VERSION ""

NS_ :

BS_:

BU_: Cooling DasFront DasRear Ecu Imu Lvac Pedals Pipo Raspberry Steering SteeringWheel TsacMainboard Acquisinator

BO_ 1278 TsacCellboard5Temperature: 8 TsacMainboard
 SG_ group M : 0|4@1+ (1,0) [0|9] "U"  Vector__XXX
 SG_ cell1 m0 : 4|11@1+ (0.1,-50) [-50|125] "degC"  Vector__XXX
 SG_ cell2 m0 : 15|11@1+ (0.1,-50) [-50|125] "degC"  Vector__XXX
 SG_ cell3 m0 : 26|11@1+ (0.1,-50) [-50|125] "degC"  Vector__XXX
 SG_ cell4 m0 : 37|11@1+ (0.1,-50) [-50|125] "degC"  Vector__XXX
 SG_ cell5 m0 : 48|11@1+ (0.1,-50) [-50|125] "degC"  Vector__XXX
 SG_ cell6 m1 : 4|11@1+ (0.1,-50) [-50|125] "degC"  Vector__XXX
 SG_ cell7 m1 : 15|11@1+ (0.1,-50) [-50|126] "degC"  Vector__XXX
 SG_ cell8 m1 : 26|11@1+ (0.1,-50) [-50|125] "degC"  Vector__XXX
 SG_ cell9 m1 : 37|11@1+ (0.1,-50) [-50|125] "degC"  Vector__XXX
 SG_ cell10 m1 : 48|11@1+ (0.1,-50) [-50|125] "degC"  Vector__XXX
 SG_ cell11 m2 : 4|11@1+ (0.1,-50) [-50|125] "degC"  Vector__XXX
 SG_ cell12 m2 : 15|11@1+ (0.1,-50) [-50|125] "degC"  Vector__XXX
 SG_ cell13 m2 : 26|11@1+ (0.1,-50) [-50|125] "degC"  Vector__XXX
 SG_ cell14 m2 : 37|11@1+ (0.1,-50) [-50|125] "degC"  Vector__XXX
 SG_ cell15 m2 : 48|11@1+ (0.1,-50) [-50|125] "degC"  Vector__XXX
 SG_ cell16 m3 : 4|11@1+ (0.1,-50) [-50|125] "degC"  Vector__XXX
 SG_ cell17 m3 : 15|11@1+ (0.1,-50) [-50|125] "degC"  Vector__XXX
 SG_ cell18 m3 : 26|11@1+ (0.1,-50) [-50|125] "degC"  Vector__XXX
 SG_ cell19 m3 : 37|11@1+ (0.1,-50) [-50|125] "degC"  Vector__XXX
 SG_ cell20 m3 : 48|11@1+ (0.1,-50) [-50|125] "degC"  Vector__XXX
 SG_ cell21 m4 : 4|11@1+ (0.1,-50) [-50|125] "degC"  Vector__XXX
 SG_ cell22 m4 : 15|11@1+ (0.1,-50) [-50|125] "degC"  Vector__XXX
 SG_ cell23 m4 : 26|11@1+ (0.1,-50) [-50|125] "degC"  Vector__XXX
 SG_ cell24 m4 : 37|11@1+ (0.1,-50) [-50|125] "degC"  Vector__XXX
 SG_ cell25 m4 : 48|11@1+ (0.1,-50) [-50|125] "degC"  Vector__XXX
 SG_ cell26 m5 : 4|11@1+ (0.1,-50) [-50|125] "degC"  Vector__XXX
 SG_ cell27 m5 : 15|11@1+ (0.1,-50) [-50|125] "degC"  Vector__XXX
 SG_ cell28 m5 : 26|11@1+ (0.1,-50) [-50|125] "degC"  Vector__XXX
 SG_ cell29 m5 : 37|11@1+ (0.1,-50) [-50|125] "degC"  Vector__XXX
 SG_ cell30 m5 : 48|11@1+ (0.1,-50) [-50|125] "degC"  Vector__XXX
 SG_ cell31 m6 : 4|11@1+ (0.1,-50) [-50|125] "degC"  Vector__XXX
 SG_ cell32 m6 : 15|11@1+ (0.1,-50) [-50|125] "degC"  Vector__XXX
 SG_ cell33 m6 : 26|11@1+ (0.1,-50) [-50|125] "degC"  Vector__XXX
 SG_ cell34 m6 : 37|11@1+ (0.1,-50) [-50|125] "degC"  Vector__XXX
 SG_ cell35 m6 : 48|11@1+ (0.1,-50) [-50|125] "degC"  Vector__XXX
 SG_ cell36 m7 : 4|11@1+ (0.1,-50) [-50|125] "degC"  Vector__XXX
 SG_ cell37 m7 : 15|11@1+ (0.1,-50) [-50|125] "degC"  Vector__XXX
 SG_ cell38 m7 : 26|11@1+ (0.1,-50) [-50|125] "degC"  Vector__XXX
 SG_ cell39 m7 : 37|11@1+ (0.1,-50) [-50|125] "degC"  Vector__XXX
 SG_ cell40 m7 : 48|11@1+ (0.1,-50) [-50|125] "degC"  Vector__XXX
 SG_ cell41 m8 : 4|11@1+ (0.1,-50) [-50|125] "degC"  Vector__XXX
 SG_ cell42 m8 : 15|11@1+ (0.1,-50) [-50|125] "degC"  Vector__XXX
 SG_ cell43 m8 : 26|11@1+ (0.1,-50) [-50|125] "degC"  Vector__XXX
 SG_ cell44 m8 : 37|11@1+ (0.1,-50) [-50|125] "degC"  Vector__XXX
 SG_ cell45 m8 : 48|11@1+ (0.1,-50) [-50|125] "degC"  Vector__XXX
 SG_ cell46 m9 : 4|11@1+ (0.1,-50) [-50|125] "degC"  Vector__XXX
 SG_ cell47 m9 : 15|11@1+ (0.1,-50) [-50|125] "degC"  Vector__XXX
 SG_ cell48 m9 : 26|11@1+ (0.1,-50) [-50|125] "degC"  Vector__XXX

BO_ 1279 TsacCellboard6Temperature: 8 TsacMainboard
 SG_ group M : 0|4@1+ (1,0) [0|9] "U"  Vector__XXX
 SG_ cell1 m0 : 4|11@1+ (0.1,-50) [-50|125] "degC"  Vector__XXX
 SG_ cell2 m0 : 15|11@1+ (0.1,-50) [-50|125] "degC"  Vector__XXX
 SG_ cell3 m0 : 26|11@1+ (0.1,-50) [-50|125] "degC"  Vector__XXX
 SG_ cell4 m0 : 37|11@1+ (0.1,-50) [-50|125] "degC"  Vector__XXX
 SG_ cell5 m0 : 48|11@1+ (0.1,-50) [-50|125] "degC"  Vector__XXX
 SG_ cell6 m1 : 4|11@1+ (0.1,-50) [-50|125] "degC"  Vector__XXX
 SG_ cell7 m1 : 15|11@1+ (0.1,-50) [-50|126] "degC"  Vector__XXX
 SG_ cell8 m1 : 26|11@1+ (0.1,-50) [-50|125] "degC"  Vector__XXX
 SG_ cell9 m1 : 37|11@1+ (0.1,-50) [-50|125] "degC"  Vector__XXX
 SG_ cell10 m1 : 48|11@1+ (0.1,-50) [-50|125] "degC"  Vector__XXX
 SG_ cell11 m2 : 4|11@1+ (0.1,-50) [-50|125] "degC"  Vector__XXX
 SG_ cell12 m2 : 15|11@1+ (0.1,-50) [-50|125] "degC"  Vector__XXX
 SG_ cell13 m2 : 26|11@1+ (0.1,-50) [-50|125] "degC"  Vector__XXX
 SG_ cell14 m2 : 37|11@1+ (0.1,-50) [-50|125] "degC"  Vector__XXX
 SG_ cell15 m2 : 48|11@1+ (0.1,-50) [-50|125] "degC"  Vector__XXX
 SG_ cell16 m3 : 4|11@1+ (0.1,-50) [-50|125] "degC"  Vector__XXX
 SG_ cell17 m3 : 15|11@1+ (0.1,-50) [-50|125] "degC"  Vector__XXX
 SG_ cell18 m3 : 26|11@1+ (0.1,-50) [-50|125] "degC"  Vector__XXX
 SG_ cell19 m3 : 37|11@1+ (0.1,-50) [-50|125] "degC"  Vector__XXX
 SG_ cell20 m3 : 48|11@1+ (0.1,-50) [-50|125] "degC"  Vector__XXX
 SG_ cell21 m4 : 4|11@1+ (0.1,-50) [-50|125] "degC"  Vector__XXX
 SG_ cell22 m4 : 15|11@1+ (0.1,-50) [-50|125] "degC"  Vector__XXX
 SG_ cell23 m4 : 26|11@1+ (0.1,-50) [-50|125] "degC"  Vector__XXX
 SG_ cell24 m4 : 37|11@1+ (0.1,-50) [-50|125] "degC"  Vector__XXX
 SG_ cell25 m4 : 48|11@1+ (0.1,-50) [-50|125] "degC"  Vector__XXX
 SG_ cell26 m5 : 4|11@1+ (0.1,-50) [-50|125] "degC"  Vector__XXX
 SG_ cell27 m5 : 15|11@1+ (0.1,-50) [-50|125] "degC"  Vector__XXX
 SG_ cell28 m5 : 26|11@1+ (0.1,-50) [-50|125] "degC"  Vector__XXX
 SG_ cell29 m5 : 37|11@1+ (0.1,-50) [-50|125] "degC"  Vector__XXX
 SG_ cell30 m5 : 48|11@1+ (0.1,-50) [-50|125] "degC"  Vector__XXX
 SG_ cell31 m6 : 4|11@1+ (0.1,-50) [-50|125] "degC"  Vector__XXX
 SG_ cell32 m6 : 15|11@1+ (0.1,-50) [-50|125] "degC"  Vector__XXX
 SG_ cell33 m6 : 26|11@1+ (0.1,-50) [-50|125] "degC"  Vector__XXX
 SG_ cell34 m6 : 37|11@1+ (0.1,-50) [-50|125] "degC"  Vector__XXX
 SG_ cell35 m6 : 48|11@1+ (0.1,-50) [-50|125] "degC"  Vector__XXX
 SG_ cell36 m7 : 4|11@1+ (0.1,-50) [-50|125] "degC"  Vector__XXX
 SG_ cell37 m7 : 15|11@1+ (0.1,-50) [-50|125] "degC"  Vector__XXX
 SG_ cell38 m7 : 26|11@1+ (0.1,-50) [-50|125] "degC"  Vector__XXX
 SG_ cell39 m7 : 37|11@1+ (0.1,-50) [-50|125] "degC"  Vector__XXX
 SG_ cell40 m7 : 48|11@1+ (0.1,-50) [-50|125] "degC"  Vector__XXX
 SG_ cell41 m8 : 4|11@1+ (0.1,-50) [-50|125] "degC"  Vector__XXX
 SG_ cell42 m8 : 15|11@1+ (0.1,-50) [-50|125] "degC"  Vector__XXX
 SG_ cell43 m8 : 26|11@1+ (0.1,-50) [-50|125] "degC"  Vector__XXX
 SG_ cell44 m8 : 37|11@1+ (0.1,-50) [-50|125] "degC"  Vector__XXX
 SG_ cell45 m8 : 48|11@1+ (0.1,-50) [-50|125] "degC"  Vector__XXX
 SG_ cell46 m9 : 4|11@1+ (0.1,-50) [-50|125] "degC"  Vector__XXX
 SG_ cell47 m9 : 15|11@1+ (0.1,-50) [-50|125] "degC"  Vector__XXX
 SG_ cell48 m9 : 26|11@1+ (0.1,-50) [-50|125] "degC"  Vector__XXX

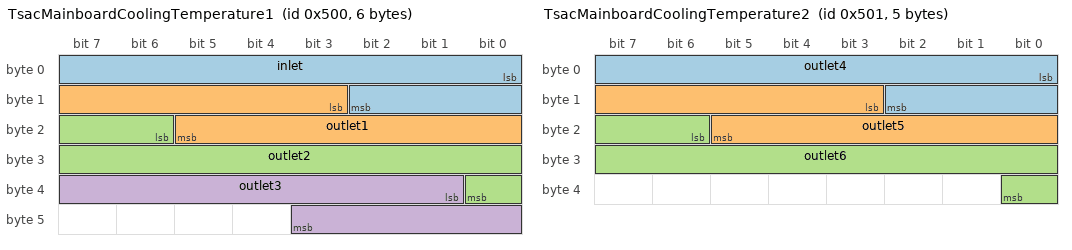
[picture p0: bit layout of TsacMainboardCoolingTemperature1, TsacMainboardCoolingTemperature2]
BO_ 1280 TsacMainboardCoolingTemperature1: 6 TsacMainboard
 SG_ inlet : 0|11@1+ (0.1,-50) [-50|125] "degC"  Vector__XXX
 SG_ outlet1 : 11|11@1+ (0.1,-50) [-50|125] "degC"  Vector__XXX
 SG_ outlet2 : 22|11@1+ (0.1,-50) [-50|125] "degC"  Vector__XXX
 SG_ outlet3 : 33|11@1+ (0.1,-50) [-50|125] "degC"  Vector__XXX

BO_ 1281 TsacMainboardCoolingTemperature2: 5 TsacMainboard
 SG_ outlet4 : 0|11@1+ (0.1,-50) [-50|125] "degC"  Vector__XXX
 SG_ outlet5 : 11|11@1+ (0.1,-50) [-50|125] "degC"  Vector__XXX
 SG_ outlet6 : 22|11@1+ (0.1,-50) [-50|125] "degC"  Vector__XXX

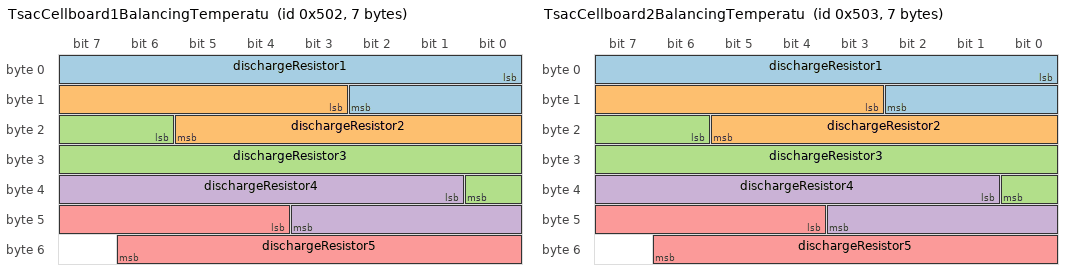
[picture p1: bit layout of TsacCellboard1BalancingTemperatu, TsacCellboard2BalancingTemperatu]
BO_ 1282 TsacCellboard1BalancingTemperatu: 7 TsacMainboard
 SG_ dischargeResistor1 : 0|11@1+ (0.1,-50) [-50|125] "degC"  Vector__XXX
 SG_ dischargeResistor2 : 11|11@1+ (0.1,-50) [-50|125] "degC"  Vector__XXX
 SG_ dischargeResistor3 : 22|11@1+ (0.1,-50) [-50|125] "degC"  Vector__XXX
 SG_ dischargeResistor4 : 33|11@1+ (0.1,-50) [-50|125] "degC"  Vector__XXX
 SG_ dischargeResistor5 : 44|11@1+ (0.1,-50) [-50|125] "degC"  Vector__XXX

BO_ 1283 TsacCellboard2BalancingTemperatu: 7 TsacMainboard
 SG_ dischargeResistor1 : 0|11@1+ (0.1,-50) [-50|125] "degC"  Vector__XXX
 SG_ dischargeResistor2 : 11|11@1+ (0.1,-50) [-50|125] "degC"  Vector__XXX
 SG_ dischargeResistor3 : 22|11@1+ (0.1,-50) [-50|125] "degC"  Vector__XXX
 SG_ dischargeResistor4 : 33|11@1+ (0.1,-50) [-50|125] "degC"  Vector__XXX
 SG_ dischargeResistor5 : 44|11@1+ (0.1,-50) [-50|125] "degC"  Vector__XXX

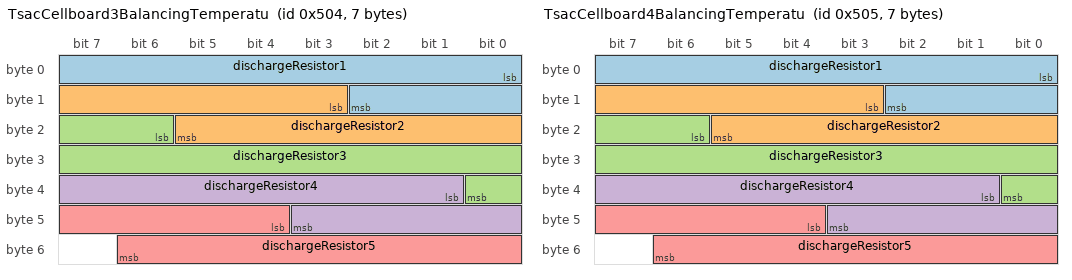
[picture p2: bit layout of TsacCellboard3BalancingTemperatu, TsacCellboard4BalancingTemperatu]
BO_ 1284 TsacCellboard3BalancingTemperatu: 7 TsacMainboard
 SG_ dischargeResistor1 : 0|11@1+ (0.1,-50) [-50|125] "degC"  Vector__XXX
 SG_ dischargeResistor2 : 11|11@1+ (0.1,-50) [-50|125] "degC"  Vector__XXX
 SG_ dischargeResistor3 : 22|11@1+ (0.1,-50) [-50|125] "degC"  Vector__XXX
 SG_ dischargeResistor4 : 33|11@1+ (0.1,-50) [-50|125] "degC"  Vector__XXX
 SG_ dischargeResistor5 : 44|11@1+ (0.1,-50) [-50|125] "degC"  Vector__XXX

BO_ 1285 TsacCellboard4BalancingTemperatu: 7 TsacMainboard
 SG_ dischargeResistor1 : 0|11@1+ (0.1,-50) [-50|125] "degC"  Vector__XXX
 SG_ dischargeResistor2 : 11|11@1+ (0.1,-50) [-50|125] "degC"  Vector__XXX
 SG_ dischargeResistor3 : 22|11@1+ (0.1,-50) [-50|125] "degC"  Vector__XXX
 SG_ dischargeResistor4 : 33|11@1+ (0.1,-50) [-50|125] "degC"  Vector__XXX
 SG_ dischargeResistor5 : 44|11@1+ (0.1,-50) [-50|125] "degC"  Vector__XXX

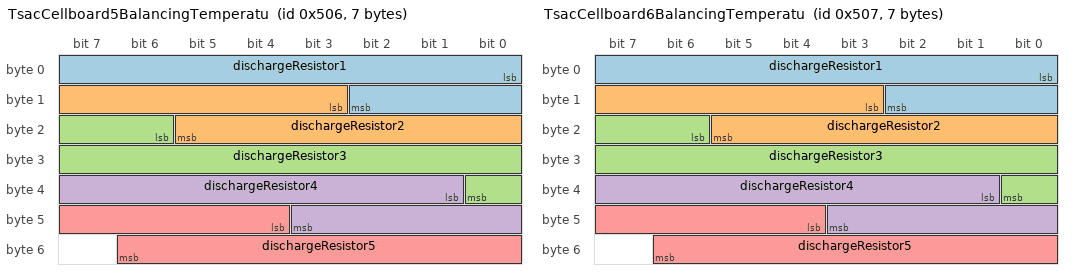
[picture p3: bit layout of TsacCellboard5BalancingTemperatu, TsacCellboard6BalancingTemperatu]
BO_ 1286 TsacCellboard5BalancingTemperatu: 7 TsacMainboard
 SG_ dischargeResistor1 : 0|11@1+ (0.1,-50) [-50|125] "degC"  Vector__XXX
 SG_ dischargeResistor2 : 11|11@1+ (0.1,-50) [-50|125] "degC"  Vector__XXX
 SG_ dischargeResistor3 : 22|11@1+ (0.1,-50) [-50|125] "degC"  Vector__XXX
 SG_ dischargeResistor4 : 33|11@1+ (0.1,-50) [-50|125] "degC"  Vector__XXX
 SG_ dischargeResistor5 : 44|11@1+ (0.1,-50) [-50|125] "degC"  Vector__XXX

BO_ 1287 TsacCellboard6BalancingTemperatu: 7 TsacMainboard
 SG_ dischargeResistor1 : 0|11@1+ (0.1,-50) [-50|125] "degC"  Vector__XXX
 SG_ dischargeResistor2 : 11|11@1+ (0.1,-50) [-50|125] "degC"  Vector__XXX
 SG_ dischargeResistor3 : 22|11@1+ (0.1,-50) [-50|125] "degC"  Vector__XXX
 SG_ dischargeResistor4 : 33|11@1+ (0.1,-50) [-50|125] "degC"  Vector__XXX
 SG_ dischargeResistor5 : 44|11@1+ (0.1,-50) [-50|125] "degC"  Vector__XXX

BO_ 1288 TsacCellboard1Balancing: 3 TsacMainboard
 SG_ cell1 : 0|1@1+ (1,0) [0|1] "bool"  Vector__XXX
 SG_ cell2 : 1|1@1+ (1,0) [0|1] "bool"  Vector__XXX
 SG_ cell3 : 2|1@1+ (1,0) [0|1] "bool"  Vector__XXX
 SG_ cell4 : 3|1@1+ (1,0) [0|1] "bool"  Vector__XXX
 SG_ cell5 : 4|1@1+ (1,0) [0|1] "bool"  Vector__XXX
 SG_ cell6 : 5|1@1+ (1,0) [0|1] "bool"  Vector__XXX
 SG_ cell7 : 6|1@1+ (1,0) [0|1] "bool"  Vector__XXX
 SG_ cell8 : 7|1@1+ (1,0) [0|1] "bool"  Vector__XXX
 SG_ cell9 : 8|1@1+ (1,0) [0|1] "bool"  Vector__XXX
 SG_ cell10 : 9|1@1+ (1,0) [0|1] "bool"  Vector__XXX
 SG_ cell11 : 10|1@1+ (1,0) [0|1] "bool"  Vector__XXX
 SG_ cell12 : 11|1@1+ (1,0) [0|1] "bool"  Vector__XXX
 SG_ cell13 : 12|1@1+ (1,0) [0|1] "bool"  Vector__XXX
 SG_ cell14 : 13|1@1+ (1,0) [0|1] "bool"  Vector__XXX
 SG_ cell15 : 14|1@1+ (1,0) [0|1] "bool"  Vector__XXX
 SG_ cell16 : 15|1@1+ (1,0) [0|1] "bool"  Vector__XXX
 SG_ cell17 : 16|1@1+ (1,0) [0|1] "bool"  Vector__XXX
 SG_ cell18 : 17|1@1+ (1,0) [0|1] "bool"  Vector__XXX
 SG_ cell19 : 18|1@1+ (1,0) [0|1] "bool"  Vector__XXX
 SG_ cell20 : 19|1@1+ (1,0) [0|1] "bool"  Vector__XXX
 SG_ cell21 : 20|1@1+ (1,0) [0|1] "bool"  Vector__XXX
 SG_ cell22 : 21|1@1+ (1,0) [0|1] "bool"  Vector__XXX
 SG_ cell23 : 22|1@1+ (1,0) [0|1] "bool"  Vector__XXX
 SG_ cell24 : 23|1@1+ (1,0) [0|1] "bool"  Vector__XXX

BO_ 1289 TsacCellboard2Balancing: 3 TsacMainboard
 SG_ cell1 : 0|1@1+ (1,0) [0|1] "bool"  Vector__XXX
 SG_ cell2 : 1|1@1+ (1,0) [0|1] "bool"  Vector__XXX
 SG_ cell3 : 2|1@1+ (1,0) [0|1] "bool"  Vector__XXX
 SG_ cell4 : 3|1@1+ (1,0) [0|1] "bool"  Vector__XXX
 SG_ cell5 : 4|1@1+ (1,0) [0|1] "bool"  Vector__XXX
 SG_ cell6 : 5|1@1+ (1,0) [0|1] "bool"  Vector__XXX
 SG_ cell7 : 6|1@1+ (1,0) [0|1] "bool"  Vector__XXX
 SG_ cell8 : 7|1@1+ (1,0) [0|1] "bool"  Vector__XXX
 SG_ cell9 : 8|1@1+ (1,0) [0|1] "bool"  Vector__XXX
 SG_ cell10 : 9|1@1+ (1,0) [0|1] "bool"  Vector__XXX
 SG_ cell11 : 10|1@1+ (1,0) [0|1] "bool"  Vector__XXX
 SG_ cell12 : 11|1@1+ (1,0) [0|1] "bool"  Vector__XXX
 SG_ cell13 : 12|1@1+ (1,0) [0|1] "bool"  Vector__XXX
 SG_ cell14 : 13|1@1+ (1,0) [0|1] "bool"  Vector__XXX
 SG_ cell15 : 14|1@1+ (1,0) [0|1] "bool"  Vector__XXX
 SG_ cell16 : 15|1@1+ (1,0) [0|1] "bool"  Vector__XXX
 SG_ cell17 : 16|1@1+ (1,0) [0|1] "bool"  Vector__XXX
 SG_ cell18 : 17|1@1+ (1,0) [0|1] "bool"  Vector__XXX
 SG_ cell19 : 18|1@1+ (1,0) [0|1] "bool"  Vector__XXX
 SG_ cell20 : 19|1@1+ (1,0) [0|1] "bool"  Vector__XXX
 SG_ cell21 : 20|1@1+ (1,0) [0|1] "bool"  Vector__XXX
 SG_ cell22 : 21|1@1+ (1,0) [0|1] "bool"  Vector__XXX
 SG_ cell23 : 22|1@1+ (1,0) [0|1] "bool"  Vector__XXX
 SG_ cell24 : 23|1@1+ (1,0) [0|1] "bool"  Vector__XXX

BO_ 1290 TsacCellboard3Balancing: 3 TsacMainboard
 SG_ cell1 : 0|1@1+ (1,0) [0|1] "bool"  Vector__XXX
 SG_ cell2 : 1|1@1+ (1,0) [0|1] "bool"  Vector__XXX
 SG_ cell3 : 2|1@1+ (1,0) [0|1] "bool"  Vector__XXX
 SG_ cell4 : 3|1@1+ (1,0) [0|1] "bool"  Vector__XXX
 SG_ cell5 : 4|1@1+ (1,0) [0|1] "bool"  Vector__XXX
 SG_ cell6 : 5|1@1+ (1,0) [0|1] "bool"  Vector__XXX
 SG_ cell7 : 6|1@1+ (1,0) [0|1] "bool"  Vector__XXX
 SG_ cell8 : 7|1@1+ (1,0) [0|1] "bool"  Vector__XXX
 SG_ cell9 : 8|1@1+ (1,0) [0|1] "bool"  Vector__XXX
 SG_ cell10 : 9|1@1+ (1,0) [0|1] "bool"  Vector__XXX
 SG_ cell11 : 10|1@1+ (1,0) [0|1] "bool"  Vector__XXX
 SG_ cell12 : 11|1@1+ (1,0) [0|1] "bool"  Vector__XXX
 SG_ cell13 : 12|1@1+ (1,0) [0|1] "bool"  Vector__XXX
 SG_ cell14 : 13|1@1+ (1,0) [0|1] "bool"  Vector__XXX
 SG_ cell15 : 14|1@1+ (1,0) [0|1] "bool"  Vector__XXX
 SG_ cell16 : 15|1@1+ (1,0) [0|1] "bool"  Vector__XXX
 SG_ cell17 : 16|1@1+ (1,0) [0|1] "bool"  Vector__XXX
 SG_ cell18 : 17|1@1+ (1,0) [0|1] "bool"  Vector__XXX
 SG_ cell19 : 18|1@1+ (1,0) [0|1] "bool"  Vector__XXX
 SG_ cell20 : 19|1@1+ (1,0) [0|1] "bool"  Vector__XXX
 SG_ cell21 : 20|1@1+ (1,0) [0|1] "bool"  Vector__XXX
 SG_ cell22 : 21|1@1+ (1,0) [0|1] "bool"  Vector__XXX
 SG_ cell23 : 22|1@1+ (1,0) [0|1] "bool"  Vector__XXX
 SG_ cell24 : 23|1@1+ (1,0) [0|1] "bool"  Vector__XXX

BO_ 1291 TsacCellboard4Balancing: 3 TsacMainboard
 SG_ cell1 : 0|1@1+ (1,0) [0|1] "bool"  Vector__XXX
 SG_ cell2 : 1|1@1+ (1,0) [0|1] "bool"  Vector__XXX
 SG_ cell3 : 2|1@1+ (1,0) [0|1] "bool"  Vector__XXX
 SG_ cell4 : 3|1@1+ (1,0) [0|1] "bool"  Vector__XXX
 SG_ cell5 : 4|1@1+ (1,0) [0|1] "bool"  Vector__XXX
 SG_ cell6 : 5|1@1+ (1,0) [0|1] "bool"  Vector__XXX
 SG_ cell7 : 6|1@1+ (1,0) [0|1] "bool"  Vector__XXX
 SG_ cell8 : 7|1@1+ (1,0) [0|1] "bool"  Vector__XXX
 SG_ cell9 : 8|1@1+ (1,0) [0|1] "bool"  Vector__XXX
 SG_ cell10 : 9|1@1+ (1,0) [0|1] "bool"  Vector__XXX
 SG_ cell11 : 10|1@1+ (1,0) [0|1] "bool"  Vector__XXX
 SG_ cell12 : 11|1@1+ (1,0) [0|1] "bool"  Vector__XXX
 SG_ cell13 : 12|1@1+ (1,0) [0|1] "bool"  Vector__XXX
 SG_ cell14 : 13|1@1+ (1,0) [0|1] "bool"  Vector__XXX
 SG_ cell15 : 14|1@1+ (1,0) [0|1] "bool"  Vector__XXX
 SG_ cell16 : 15|1@1+ (1,0) [0|1] "bool"  Vector__XXX
 SG_ cell17 : 16|1@1+ (1,0) [0|1] "bool"  Vector__XXX
 SG_ cell18 : 17|1@1+ (1,0) [0|1] "bool"  Vector__XXX
 SG_ cell19 : 18|1@1+ (1,0) [0|1] "bool"  Vector__XXX
 SG_ cell20 : 19|1@1+ (1,0) [0|1] "bool"  Vector__XXX
 SG_ cell21 : 20|1@1+ (1,0) [0|1] "bool"  Vector__XXX
 SG_ cell22 : 21|1@1+ (1,0) [0|1] "bool"  Vector__XXX
 SG_ cell23 : 22|1@1+ (1,0) [0|1] "bool"  Vector__XXX
 SG_ cell24 : 23|1@1+ (1,0) [0|1] "bool"  Vector__XXX

BO_ 1292 TsacCellboard5Balancing: 3 TsacMainboard
 SG_ cell1 : 0|1@1+ (1,0) [0|1] "bool"  Vector__XXX
 SG_ cell2 : 1|1@1+ (1,0) [0|1] "bool"  Vector__XXX
 SG_ cell3 : 2|1@1+ (1,0) [0|1] "bool"  Vector__XXX
 SG_ cell4 : 3|1@1+ (1,0) [0|1] "bool"  Vector__XXX
 SG_ cell5 : 4|1@1+ (1,0) [0|1] "bool"  Vector__XXX
 SG_ cell6 : 5|1@1+ (1,0) [0|1] "bool"  Vector__XXX
 SG_ cell7 : 6|1@1+ (1,0) [0|1] "bool"  Vector__XXX
 SG_ cell8 : 7|1@1+ (1,0) [0|1] "bool"  Vector__XXX
 SG_ cell9 : 8|1@1+ (1,0) [0|1] "bool"  Vector__XXX
 SG_ cell10 : 9|1@1+ (1,0) [0|1] "bool"  Vector__XXX
 SG_ cell11 : 10|1@1+ (1,0) [0|1] "bool"  Vector__XXX
 SG_ cell12 : 11|1@1+ (1,0) [0|1] "bool"  Vector__XXX
 SG_ cell13 : 12|1@1+ (1,0) [0|1] "bool"  Vector__XXX
 SG_ cell14 : 13|1@1+ (1,0) [0|1] "bool"  Vector__XXX
 SG_ cell15 : 14|1@1+ (1,0) [0|1] "bool"  Vector__XXX
 SG_ cell16 : 15|1@1+ (1,0) [0|1] "bool"  Vector__XXX
 SG_ cell17 : 16|1@1+ (1,0) [0|1] "bool"  Vector__XXX
 SG_ cell18 : 17|1@1+ (1,0) [0|1] "bool"  Vector__XXX
 SG_ cell19 : 18|1@1+ (1,0) [0|1] "bool"  Vector__XXX
 SG_ cell20 : 19|1@1+ (1,0) [0|1] "bool"  Vector__XXX
 SG_ cell21 : 20|1@1+ (1,0) [0|1] "bool"  Vector__XXX
 SG_ cell22 : 21|1@1+ (1,0) [0|1] "bool"  Vector__XXX
 SG_ cell23 : 22|1@1+ (1,0) [0|1] "bool"  Vector__XXX
 SG_ cell24 : 23|1@1+ (1,0) [0|1] "bool"  Vector__XXX

BO_ 1293 TsacCellboard6Balancing: 3 TsacMainboard
 SG_ cell1 : 0|1@1+ (1,0) [0|1] "bool"  Vector__XXX
 SG_ cell2 : 1|1@1+ (1,0) [0|1] "bool"  Vector__XXX
 SG_ cell3 : 2|1@1+ (1,0) [0|1] "bool"  Vector__XXX
 SG_ cell4 : 3|1@1+ (1,0) [0|1] "bool"  Vector__XXX
 SG_ cell5 : 4|1@1+ (1,0) [0|1] "bool"  Vector__XXX
 SG_ cell6 : 5|1@1+ (1,0) [0|1] "bool"  Vector__XXX
 SG_ cell7 : 6|1@1+ (1,0) [0|1] "bool"  Vector__XXX
 SG_ cell8 : 7|1@1+ (1,0) [0|1] "bool"  Vector__XXX
 SG_ cell9 : 8|1@1+ (1,0) [0|1] "bool"  Vector__XXX
 SG_ cell10 : 9|1@1+ (1,0) [0|1] "bool"  Vector__XXX
 SG_ cell11 : 10|1@1+ (1,0) [0|1] "bool"  Vector__XXX
 SG_ cell12 : 11|1@1+ (1,0) [0|1] "bool"  Vector__XXX
 SG_ cell13 : 12|1@1+ (1,0) [0|1] "bool"  Vector__XXX
 SG_ cell14 : 13|1@1+ (1,0) [0|1] "bool"  Vector__XXX
 SG_ cell15 : 14|1@1+ (1,0) [0|1] "bool"  Vector__XXX
 SG_ cell16 : 15|1@1+ (1,0) [0|1] "bool"  Vector__XXX
 SG_ cell17 : 16|1@1+ (1,0) [0|1] "bool"  Vector__XXX
 SG_ cell18 : 17|1@1+ (1,0) [0|1] "bool"  Vector__XXX
 SG_ cell19 : 18|1@1+ (1,0) [0|1] "bool"  Vector__XXX
 SG_ cell20 : 19|1@1+ (1,0) [0|1] "bool"  Vector__XXX
 SG_ cell21 : 20|1@1+ (1,0) [0|1] "bool"  Vector__XXX
 SG_ cell22 : 21|1@1+ (1,0) [0|1] "bool"  Vector__XXX
 SG_ cell23 : 22|1@1+ (1,0) [0|1] "bool"  Vector__XXX
 SG_ cell24 : 23|1@1+ (1,0) [0|1] "bool"  Vector__XXX

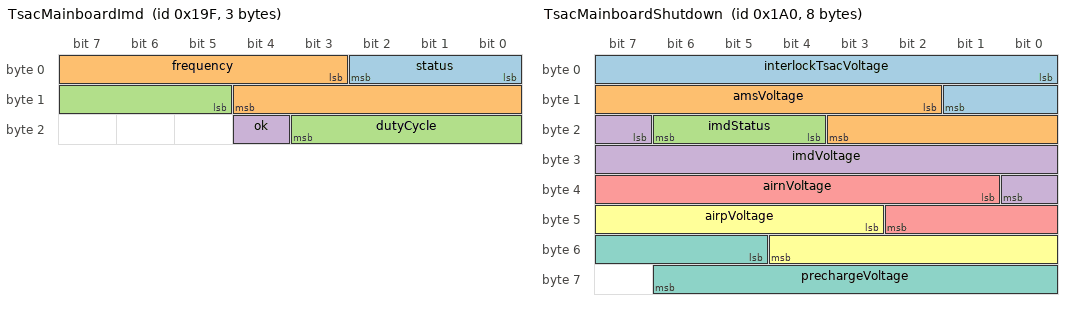
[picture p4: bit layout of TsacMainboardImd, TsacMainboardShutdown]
BO_ 415 TsacMainboardImd: 3 TsacMainboard
 SG_ status : 0|3@1+ (1,0) [0|0] "enum"  Vector__XXX
 SG_ frequency : 3|10@1+ (0.1,0) [0|70] "Hz"  Vector__XXX
 SG_ dutyCycle : 13|7@1+ (0.01,0) [0|1] "U"  Vector__XXX
 SG_ ok : 20|1@1+ (1,0) [0|1] "bool"  Vector__XXX

BO_ 416 TsacMainboardShutdown: 8 TsacMainboard
 SG_ interlockTsacVoltage : 0|10@1+ (0.03,0) [0|27] "V"  Vector__XXX
 SG_ amsVoltage : 10|10@1+ (0.03,0) [0|27] "V"  Vector__XXX
 SG_ imdStatus : 20|3@1+ (1,0) [0|0] "enum"  Vector__XXX
 SG_ imdVoltage : 23|10@1+ (0.03,0) [0|27] "V"  Vector__XXX
 SG_ airnVoltage : 33|10@1+ (0.03,0) [0|27] "V"  Vector__XXX
 SG_ airpVoltage : 43|10@1+ (0.03,0) [0|27] "V"  Vector__XXX
 SG_ prechargeVoltage : 53|10@1+ (0.03,0) [0|27] "V"  Vector__XXX

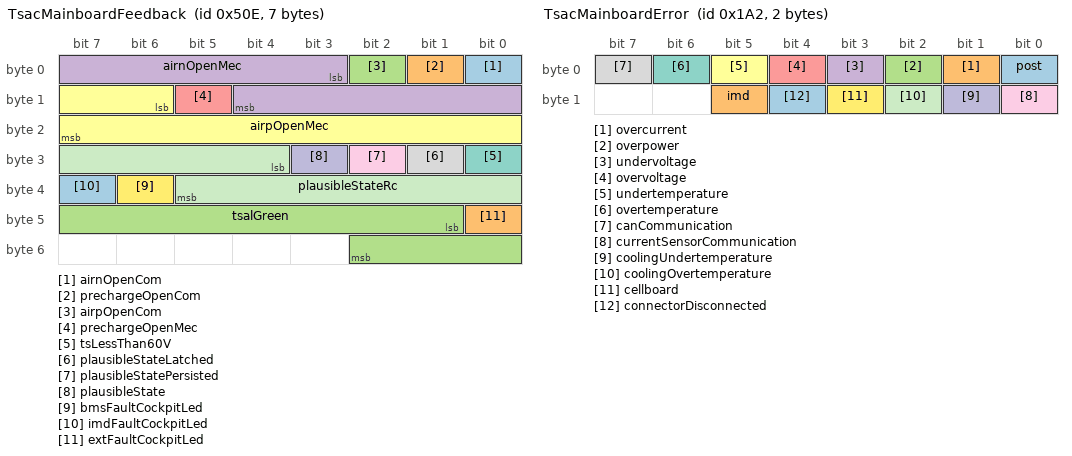
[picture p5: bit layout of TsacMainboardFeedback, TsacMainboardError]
BO_ 1294 TsacMainboardFeedback: 7 TsacMainboard
 SG_ airnOpenCom : 0|1@1+ (1,0) [0|1] "bool"  Vector__XXX
 SG_ prechargeOpenCom : 1|1@1+ (1,0) [0|1] "bool"  Vector__XXX
 SG_ airpOpenCom : 2|1@1+ (1,0) [0|1] "bool"  Vector__XXX
 SG_ airnOpenMec : 3|10@1+ (0.03,0) [0|27] "V"  Vector__XXX
 SG_ prechargeOpenMec : 13|1@1+ (1,0) [0|1] "bool"  Vector__XXX
 SG_ airpOpenMec : 14|10@1+ (0.03,0) [0|27] "V"  Vector__XXX
 SG_ tsLessThan60V : 24|1@1+ (1,0) [0|1] "bool"  Vector__XXX
 SG_ plausibleStateLatched : 25|1@1+ (1,0) [0|1] "bool"  Vector__XXX
 SG_ plausibleStatePersisted : 26|1@1+ (1,0) [0|1] "bool"  Vector__XXX
 SG_ plausibleState : 27|1@1+ (1,0) [0|1] "bool"  Vector__XXX
 SG_ plausibleStateRc : 28|10@1+ (0.03,0) [0|27] "V"  Vector__XXX
 SG_ bmsFaultCockpitLed : 38|1@1+ (1,0) [0|1] "bool"  Vector__XXX
 SG_ imdFaultCockpitLed : 39|1@1+ (1,0) [0|1] "bool"  Vector__XXX
 SG_ extFaultCockpitLed : 40|1@1+ (1,0) [0|1] "bool"  Vector__XXX
 SG_ tsalGreen : 41|10@1+ (0.03,0) [0|27] "V"  Vector__XXX

BO_ 417 TsacMainboardFeedbackShutdown: 3 TsacMainboard
 SG_ sdIn : 0|10@1+ (0.03,0) [0|27] "V"  Vector__XXX
 SG_ sdEnd : 10|10@1+ (0.03,0) [0|27] "V"  Vector__XXX

BO_ 418 TsacMainboardError: 2 TsacMainboard
 SG_ post : 0|1@1+ (1,0) [0|1] "bool"  Vector__XXX
 SG_ overcurrent : 1|1@1+ (1,0) [0|1] "bool"  Vector__XXX
 SG_ overpower : 2|1@1+ (1,0) [0|1] "bool"  Vector__XXX
 SG_ undervoltage : 3|1@1+ (1,0) [0|1] "bool"  Vector__XXX
 SG_ overvoltage : 4|1@1+ (1,0) [0|1] "bool"  Vector__XXX
 SG_ undertemperature : 5|1@1+ (1,0) [0|1] "bool"  Vector__XXX
 SG_ overtemperature : 6|1@1+ (1,0) [0|1] "bool"  Vector__XXX
 SG_ canCommunication : 7|1@1+ (1,0) [0|1] "bool"  Vector__XXX
 SG_ currentSensorCommunication : 8|1@1+ (1,0) [0|1] "bool"  Vector__XXX
 SG_ coolingUndertemperature : 9|1@1+ (1,0) [0|1] "bool"  Vector__XXX
 SG_ coolingOvertemperature : 10|1@1+ (1,0) [0|1] "bool"  Vector__XXX
 SG_ cellboard : 11|1@1+ (1,0) [0|1] "bool"  Vector__XXX
 SG_ connectorDisconnected : 12|1@1+ (1,0) [0|1] "bool"  Vector__XXX
 SG_ imd : 13|1@1+ (1,0) [0|1] "bool"  Vector__XXX

BO_ 419 TsacCellboardErrorA: 6 TsacMainboard
 SG_ cellboard1Post : 0|1@1+ (1,0) [0|1] "bool"  Vector__XXX
 SG_ cellboard1CellUndervoltage : 1|1@1+ (1,0) [0|1] "bool"  Vector__XXX
 SG_ cellboard1CellOvervoltage : 2|1@1+ (1,0) [0|1] "bool"  Vector__XXX
 SG_ cellboard1CellUndertemperature : 3|1@1+ (1,0) [0|1] "bool"  Vector__XXX
 SG_ cellboard1CellOvertemperature : 4|1@1+ (1,0) [0|1] "bool"  Vector__XXX
 SG_ cellboard1DischargeResistorUnder : 5|1@1+ (1,0) [0|1] "bool"  Vector__XXX
 SG_ cellboard1DischargeResistorOvert : 6|1@1+ (1,0) [0|1] "bool"  Vector__XXX
 SG_ cellboard1CanCommunication : 7|1@1+ (1,0) [0|1] "bool"  Vector__XXX
 SG_ cellboard1Flash : 8|1@1+ (1,0) [0|1] "bool"  Vector__XXX
 SG_ cellboard1BmsMonitorCommunicatio : 9|1@1+ (1,0) [0|1] "bool"  Vector__XXX
 SG_ cellboard1OpenWire1 : 10|1@1+ (1,0) [0|1] "bool"  Vector__XXX
 SG_ cellboard1OpenWire2 : 11|1@1+ (1,0) [0|1] "bool"  Vector__XXX
 SG_ cellboard1OpenWire3 : 12|1@1+ (1,0) [0|1] "bool"  Vector__XXX
 SG_ cellboard1OpenWire4 : 13|1@1+ (1,0) [0|1] "bool"  Vector__XXX
 SG_ cellboard1OpenWire5 : 14|1@1+ (1,0) [0|1] "bool"  Vector__XXX
 SG_ cellboard1OpenWire6 : 15|1@1+ (1,0) [0|1] "bool"  Vector__XXX
 SG_ cellboard1OpenWire7 : 16|1@1+ (1,0) [0|1] "bool"  Vector__XXX
 SG_ cellboard1OpenWire8 : 17|1@1+ (1,0) [0|1] "bool"  Vector__XXX
 SG_ cellboard1OpenWire9 : 18|1@1+ (1,0) [0|1] "bool"  Vector__XXX
 SG_ cellboard1OpenWire10 : 19|1@1+ (1,0) [0|1] "bool"  Vector__XXX
 SG_ cellboard1OpenWire11 : 20|1@1+ (1,0) [0|1] "bool"  Vector__XXX
 SG_ cellboard1OpenWire12 : 21|1@1+ (1,0) [0|1] "bool"  Vector__XXX
 SG_ cellboard1OpenWire13 : 22|1@1+ (1,0) [0|1] "bool"  Vector__XXX
 SG_ cellboard2Post : 23|1@1+ (1,0) [0|1] "bool"  Vector__XXX
 SG_ cellboard2CellUndervoltage : 24|1@1+ (1,0) [0|1] "bool"  Vector__XXX
 SG_ cellboard2CellOvervoltage : 25|1@1+ (1,0) [0|1] "bool"  Vector__XXX
 SG_ cellboard2CellUndertemperature : 26|1@1+ (1,0) [0|1] "bool"  Vector__XXX
 SG_ cellboard2CellOvertemperature : 27|1@1+ (1,0) [0|1] "bool"  Vector__XXX
 SG_ cellboard2DischargeResistorUnder : 28|1@1+ (1,0) [0|1] "bool"  Vector__XXX
 SG_ cellboard2DischargeResistorOvert : 29|1@1+ (1,0) [0|1] "bool"  Vector__XXX
 SG_ cellboard2CanCommunication : 30|1@1+ (1,0) [0|1] "bool"  Vector__XXX
 SG_ cellboard2Flash : 31|1@1+ (1,0) [0|1] "bool"  Vector__XXX
 SG_ cellboard2BmsMonitorCommunicatio : 32|1@1+ (1,0) [0|1] "bool"  Vector__XXX
 SG_ cellboard2OpenWire1 : 33|1@1+ (1,0) [0|1] "bool"  Vector__XXX
 SG_ cellboard2OpenWire2 : 34|1@1+ (1,0) [0|1] "bool"  Vector__XXX
 SG_ cellboard2OpenWire3 : 35|1@1+ (1,0) [0|1] "bool"  Vector__XXX
 SG_ cellboard2OpenWire4 : 36|1@1+ (1,0) [0|1] "bool"  Vector__XXX
 SG_ cellboard2OpenWire5 : 37|1@1+ (1,0) [0|1] "bool"  Vector__XXX
 SG_ cellboard2OpenWire6 : 38|1@1+ (1,0) [0|1] "bool"  Vector__XXX
 SG_ cellboard2OpenWire7 : 39|1@1+ (1,0) [0|1] "bool"  Vector__XXX
 SG_ cellboard2OpenWire8 : 40|1@1+ (1,0) [0|1] "bool"  Vector__XXX
 SG_ cellboard2OpenWire9 : 41|1@1+ (1,0) [0|1] "bool"  Vector__XXX
 SG_ cellboard2OpenWire10 : 42|1@1+ (1,0) [0|1] "bool"  Vector__XXX
 SG_ cellboard2OpenWire11 : 43|1@1+ (1,0) [0|1] "bool"  Vector__XXX
 SG_ cellboard2OpenWire12 : 44|1@1+ (1,0) [0|1] "bool"  Vector__XXX
 SG_ cellboard2OpenWire13 : 45|1@1+ (1,0) [0|1] "bool"  Vector__XXX

BO_ 420 TsacCellboardErrorB: 6 TsacMainboard
 SG_ cellboard3Post : 0|1@1+ (1,0) [0|1] "bool"  Vector__XXX
 SG_ cellboard3CellUndervoltage : 1|1@1+ (1,0) [0|1] "bool"  Vector__XXX
 SG_ cellboard3CellOvervoltage : 2|1@1+ (1,0) [0|1] "bool"  Vector__XXX
 SG_ cellboard3CellUndertemperature : 3|1@1+ (1,0) [0|1] "bool"  Vector__XXX
 SG_ cellboard3CellOvertemperature : 4|1@1+ (1,0) [0|1] "bool"  Vector__XXX
 SG_ cellboard3DischargeResistorUnder : 5|1@1+ (1,0) [0|1] "bool"  Vector__XXX
 SG_ cellboard3DischargeResistorOvert : 6|1@1+ (1,0) [0|1] "bool"  Vector__XXX
 SG_ cellboard3CanCommunication : 7|1@1+ (1,0) [0|1] "bool"  Vector__XXX
 SG_ cellboard3Flash : 8|1@1+ (1,0) [0|1] "bool"  Vector__XXX
 SG_ cellboard3BmsMonitorCommunicatio : 9|1@1+ (1,0) [0|1] "bool"  Vector__XXX
 SG_ cellboard3OpenWire1 : 10|1@1+ (1,0) [0|1] "bool"  Vector__XXX
 SG_ cellboard3OpenWire2 : 11|1@1+ (1,0) [0|1] "bool"  Vector__XXX
 SG_ cellboard3OpenWire3 : 12|1@1+ (1,0) [0|1] "bool"  Vector__XXX
 SG_ cellboard3OpenWire4 : 13|1@1+ (1,0) [0|1] "bool"  Vector__XXX
 SG_ cellboard3OpenWire5 : 14|1@1+ (1,0) [0|1] "bool"  Vector__XXX
 SG_ cellboard3OpenWire6 : 15|1@1+ (1,0) [0|1] "bool"  Vector__XXX
 SG_ cellboard3OpenWire7 : 16|1@1+ (1,0) [0|1] "bool"  Vector__XXX
 SG_ cellboard3OpenWire8 : 17|1@1+ (1,0) [0|1] "bool"  Vector__XXX
 SG_ cellboard3OpenWire9 : 18|1@1+ (1,0) [0|1] "bool"  Vector__XXX
 SG_ cellboard3OpenWire10 : 19|1@1+ (1,0) [0|1] "bool"  Vector__XXX
 SG_ cellboard3OpenWire11 : 20|1@1+ (1,0) [0|1] "bool"  Vector__XXX
 SG_ cellboard3OpenWire12 : 21|1@1+ (1,0) [0|1] "bool"  Vector__XXX
 SG_ cellboard3OpenWire13 : 22|1@1+ (1,0) [0|1] "bool"  Vector__XXX
 SG_ cellboard4Post : 23|1@1+ (1,0) [0|1] "bool"  Vector__XXX
 SG_ cellboard4CellUndervoltage : 24|1@1+ (1,0) [0|1] "bool"  Vector__XXX
 SG_ cellboard4CellOvervoltage : 25|1@1+ (1,0) [0|1] "bool"  Vector__XXX
 SG_ cellboard4CellUndertemperature : 26|1@1+ (1,0) [0|1] "bool"  Vector__XXX
 SG_ cellboard4CellOvertemperature : 27|1@1+ (1,0) [0|1] "bool"  Vector__XXX
 SG_ cellboard4DischargeResistorUnder : 28|1@1+ (1,0) [0|1] "bool"  Vector__XXX
 SG_ cellboard4DischargeResistorOvert : 29|1@1+ (1,0) [0|1] "bool"  Vector__XXX
 SG_ cellboard4CanCommunication : 30|1@1+ (1,0) [0|1] "bool"  Vector__XXX
 SG_ cellboard4Flash : 31|1@1+ (1,0) [0|1] "bool"  Vector__XXX
 SG_ cellboard4BmsMonitorCommunicatio : 32|1@1+ (1,0) [0|1] "bool"  Vector__XXX
 SG_ cellboard4OpenWire1 : 33|1@1+ (1,0) [0|1] "bool"  Vector__XXX
 SG_ cellboard4OpenWire2 : 34|1@1+ (1,0) [0|1] "bool"  Vector__XXX
 SG_ cellboard4OpenWire3 : 35|1@1+ (1,0) [0|1] "bool"  Vector__XXX
 SG_ cellboard4OpenWire4 : 36|1@1+ (1,0) [0|1] "bool"  Vector__XXX
 SG_ cellboard4OpenWire5 : 37|1@1+ (1,0) [0|1] "bool"  Vector__XXX
 SG_ cellboard4OpenWire6 : 38|1@1+ (1,0) [0|1] "bool"  Vector__XXX
 SG_ cellboard4OpenWire7 : 39|1@1+ (1,0) [0|1] "bool"  Vector__XXX
 SG_ cellboard4OpenWire8 : 40|1@1+ (1,0) [0|1] "bool"  Vector__XXX
 SG_ cellboard4OpenWire9 : 41|1@1+ (1,0) [0|1] "bool"  Vector__XXX
 SG_ cellboard4OpenWire10 : 42|1@1+ (1,0) [0|1] "bool"  Vector__XXX
 SG_ cellboard4OpenWire11 : 43|1@1+ (1,0) [0|1] "bool"  Vector__XXX
 SG_ cellboard4OpenWire12 : 44|1@1+ (1,0) [0|1] "bool"  Vector__XXX
 SG_ cellboard4OpenWire13 : 45|1@1+ (1,0) [0|1] "bool"  Vector__XXX

BO_ 421 TsacCellboardErrorC: 6 TsacMainboard
 SG_ cellboard5Post : 0|1@1+ (1,0) [0|1] "bool"  Vector__XXX
 SG_ cellboard5CellUndervoltage : 1|1@1+ (1,0) [0|1] "bool"  Vector__XXX
 SG_ cellboard5CellOvervoltage : 2|1@1+ (1,0) [0|1] "bool"  Vector__XXX
 SG_ cellboard5CellUndertemperature : 3|1@1+ (1,0) [0|1] "bool"  Vector__XXX
 SG_ cellboard5CellOvertemperature : 4|1@1+ (1,0) [0|1] "bool"  Vector__XXX
 SG_ cellboard5DischargeResistorUnder : 5|1@1+ (1,0) [0|1] "bool"  Vector__XXX
 SG_ cellboard5DischargeResistorOvert : 6|1@1+ (1,0) [0|1] "bool"  Vector__XXX
 SG_ cellboard5CanCommunication : 7|1@1+ (1,0) [0|1] "bool"  Vector__XXX
 SG_ cellboard5Flash : 8|1@1+ (1,0) [0|1] "bool"  Vector__XXX
 SG_ cellboard5BmsMonitorCommunicatio : 9|1@1+ (1,0) [0|1] "bool"  Vector__XXX
 SG_ cellboard5OpenWire1 : 10|1@1+ (1,0) [0|1] "bool"  Vector__XXX
 SG_ cellboard5OpenWire2 : 11|1@1+ (1,0) [0|1] "bool"  Vector__XXX
 SG_ cellboard5OpenWire3 : 12|1@1+ (1,0) [0|1] "bool"  Vector__XXX
 SG_ cellboard5OpenWire4 : 13|1@1+ (1,0) [0|1] "bool"  Vector__XXX
 SG_ cellboard5OpenWire5 : 14|1@1+ (1,0) [0|1] "bool"  Vector__XXX
 SG_ cellboard5OpenWire6 : 15|1@1+ (1,0) [0|1] "bool"  Vector__XXX
 SG_ cellboard5OpenWire7 : 16|1@1+ (1,0) [0|1] "bool"  Vector__XXX
 SG_ cellboard5OpenWire8 : 17|1@1+ (1,0) [0|1] "bool"  Vector__XXX
 SG_ cellboard5OpenWire9 : 18|1@1+ (1,0) [0|1] "bool"  Vector__XXX
 SG_ cellboard5OpenWire10 : 19|1@1+ (1,0) [0|1] "bool"  Vector__XXX
 SG_ cellboard5OpenWire11 : 20|1@1+ (1,0) [0|1] "bool"  Vector__XXX
 SG_ cellboard5OpenWire12 : 21|1@1+ (1,0) [0|1] "bool"  Vector__XXX
 SG_ cellboard5OpenWire13 : 22|1@1+ (1,0) [0|1] "bool"  Vector__XXX
 SG_ cellboard6Post : 23|1@1+ (1,0) [0|1] "bool"  Vector__XXX
 SG_ cellboard6CellUndervoltage : 24|1@1+ (1,0) [0|1] "bool"  Vector__XXX
 SG_ cellboard6CellOvervoltage : 25|1@1+ (1,0) [0|1] "bool"  Vector__XXX
 SG_ cellboard6CellUndertemperature : 26|1@1+ (1,0) [0|1] "bool"  Vector__XXX
 SG_ cellboard6CellOvertemperature : 27|1@1+ (1,0) [0|1] "bool"  Vector__XXX
 SG_ cellboard6DischargeResistorUnder : 28|1@1+ (1,0) [0|1] "bool"  Vector__XXX
 SG_ cellboard6DischargeResistorOvert : 29|1@1+ (1,0) [0|1] "bool"  Vector__XXX
 SG_ cellboard6CanCommunication : 30|1@1+ (1,0) [0|1] "bool"  Vector__XXX
 SG_ cellboard6Flash : 31|1@1+ (1,0) [0|1] "bool"  Vector__XXX
 SG_ cellboard6BmsMonitorCommunicatio : 32|1@1+ (1,0) [0|1] "bool"  Vector__XXX
 SG_ cellboard6OpenWire1 : 33|1@1+ (1,0) [0|1] "bool"  Vector__XXX
 SG_ cellboard6OpenWire2 : 34|1@1+ (1,0) [0|1] "bool"  Vector__XXX
 SG_ cellboard6OpenWire3 : 35|1@1+ (1,0) [0|1] "bool"  Vector__XXX
 SG_ cellboard6OpenWire4 : 36|1@1+ (1,0) [0|1] "bool"  Vector__XXX
 SG_ cellboard6OpenWire5 : 37|1@1+ (1,0) [0|1] "bool"  Vector__XXX
 SG_ cellboard6OpenWire6 : 38|1@1+ (1,0) [0|1] "bool"  Vector__XXX
 SG_ cellboard6OpenWire7 : 39|1@1+ (1,0) [0|1] "bool"  Vector__XXX
 SG_ cellboard6OpenWire8 : 40|1@1+ (1,0) [0|1] "bool"  Vector__XXX
 SG_ cellboard6OpenWire9 : 41|1@1+ (1,0) [0|1] "bool"  Vector__XXX
 SG_ cellboard6OpenWire10 : 42|1@1+ (1,0) [0|1] "bool"  Vector__XXX
 SG_ cellboard6OpenWire11 : 43|1@1+ (1,0) [0|1] "bool"  Vector__XXX
 SG_ cellboard6OpenWire12 : 44|1@1+ (1,0) [0|1] "bool"  Vector__XXX
 SG_ cellboard6OpenWire13 : 45|1@1+ (1,0) [0|1] "bool"  Vector__XXX

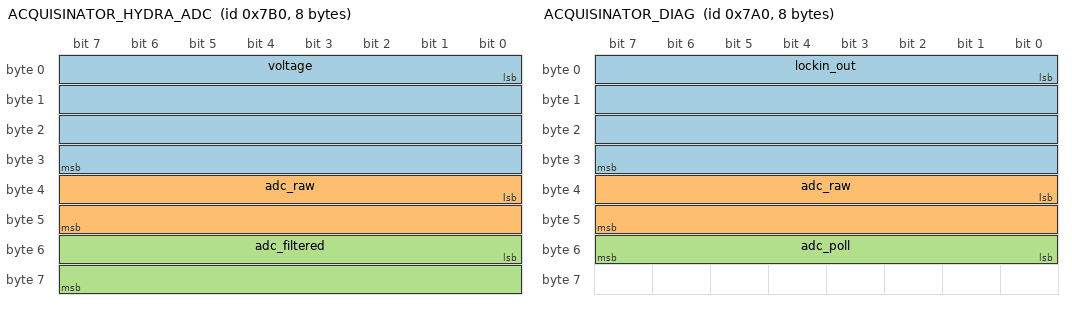
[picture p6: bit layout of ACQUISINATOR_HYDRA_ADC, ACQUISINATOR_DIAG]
BO_ 1968 ACQUISINATOR_HYDRA_ADC: 8 Acquisinator
 SG_ voltage : 0|32@1- (1,0) [0|3290] "mV" Vector__XXX
 SG_ adc_raw : 32|16@1+ (1,0) [0|65535] "code" Vector__XXX
 SG_ adc_filtered : 48|16@1+ (1,0) [0|65535] "code" Vector__XXX

BO_ 1952 ACQUISINATOR_DIAG: 8 Acquisinator
 SG_ lockin_out : 0|32@1+ (1,0) [0|0] "V" Vector__XXX
 SG_ adc_raw : 32|16@1+ (1,0) [0|65535] "code" Vector__XXX
 SG_ adc_poll : 48|8@1+ (1,0) [0|255] "status" Vector__XXX

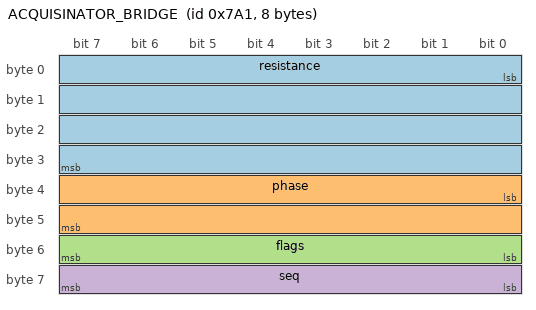
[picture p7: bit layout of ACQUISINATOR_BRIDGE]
BO_ 1953 ACQUISINATOR_BRIDGE: 8 Acquisinator
 SG_ resistance : 0|32@1+ (1,0) [0|0] "ohm" Vector__XXX
 SG_ phase : 32|16@1- (0.01,0) [-180|180] "deg" Vector__XXX
 SG_ flags : 48|8@1+ (1,0) [0|255] "" Vector__XXX
 SG_ seq : 56|8@1+ (1,0) [0|255] "" Vector__XXX

CM_ SG_ 1968 voltage "Tensione sul canale dell'estensimetro (uscita amplificatore), da adc_filtered: 3290 mV * media / 65536";
CM_ SG_ 1968 adc_raw "Ultimo campione dell'LTC1865 (canale SE_CH2), non filtrato; campionamento a 1.5 kHz da timer, frame a ACQUISINATORE_ADC_SEND_RATE";
CM_ SG_ 1968 adc_filtered "Campioni a 1.5 kHz filtrati dal firmware (ACQUISINATORE_ADC_FILTER: media su 20 ms, oppure notch 50/100/150 Hz + passa basso a SEND_RATE/4), arrotondati; voltage ha il valore non arrotondato";
CM_ SG_ 1952 lockin_out "Componente in fase all'uscita dell'amplificatore, ampiezza di picco con segno";
CM_ SG_ 1952 adc_raw "Media dell'uscita dell'amplificatore sulla finestra";
CM_ SG_ 1953 flags "bit0 saturazione bassa, bit1 saturazione alta, bit2 errore SPI, bit3 non calibrato, bit4 nessuna misura (resistance = NaN)";
BA_DEF_ SG_  "StandardName" STRING ;
BA_DEF_ SG_  "SignalTypeName" STRING ;
BA_DEF_ SG_  "SignalType" STRING ;
BA_DEF_ SG_  "Bitfield" STRING ;
BA_DEF_ BO_  "SystemMessageLongSymbol" STRING ;
BA_DEF_ SG_  "SystemSignalLongSymbol" STRING ;
BA_DEF_ BO_  "GenMsgCycleTime" INT 0 65535;
BA_DEF_DEF_  "StandardName" "";
BA_DEF_DEF_  "SignalTypeName" "";
BA_DEF_DEF_  "SignalType" "";
BA_DEF_DEF_  "Bitfield" "false";
BA_DEF_DEF_  "SystemMessageLongSymbol" "";
BA_DEF_DEF_  "SystemSignalLongSymbol" "";
BA_DEF_DEF_  "GenMsgCycleTime" 0;
BA_ "StandardName" SG_ 1278 cell45 "Kraken_TsacCellboard5Temperature_cell45_degC";
BA_ "StandardName" SG_ 1278 cell40 "Kraken_TsacCellboard5Temperature_cell40_degC";
BA_ "StandardName" SG_ 1278 cell35 "Kraken_TsacCellboard5Temperature_cell35_degC";
BA_ "StandardName" SG_ 1278 cell30 "Kraken_TsacCellboard5Temperature_cell30_degC";
BA_ "StandardName" SG_ 1278 cell25 "Kraken_TsacCellboard5Temperature_cell25_degC";
BA_ "StandardName" SG_ 1278 cell20 "Kraken_TsacCellboard5Temperature_cell20_degC";
BA_ "StandardName" SG_ 1278 cell15 "Kraken_TsacCellboard5Temperature_cell15_degC";
BA_ "StandardName" SG_ 1278 cell10 "Kraken_TsacCellboard5Temperature_cell10_degC";
BA_ "StandardName" SG_ 1278 cell5 "Kraken_TsacCellboard5Temperature_cell5_degC";
BA_ "StandardName" SG_ 1278 cell44 "Kraken_TsacCellboard5Temperature_cell44_degC";
BA_ "StandardName" SG_ 1278 cell39 "Kraken_TsacCellboard5Temperature_cell39_degC";
BA_ "StandardName" SG_ 1278 cell34 "Kraken_TsacCellboard5Temperature_cell34_degC";
BA_ "StandardName" SG_ 1278 cell29 "Kraken_TsacCellboard5Temperature_cell29_degC";
BA_ "StandardName" SG_ 1278 cell24 "Kraken_TsacCellboard5Temperature_cell24_degC";
BA_ "StandardName" SG_ 1278 cell19 "Kraken_TsacCellboard5Temperature_cell19_degC";
BA_ "StandardName" SG_ 1278 cell14 "Kraken_TsacCellboard5Temperature_cell14_degC";
BA_ "StandardName" SG_ 1278 cell9 "Kraken_TsacCellboard5Temperature_cell9_degC";
BA_ "StandardName" SG_ 1278 cell4 "Kraken_TsacCellboard5Temperature_cell4_degC";
BA_ "StandardName" SG_ 1278 cell48 "Kraken_TsacCellboard5Temperature_cell48_degC";
BA_ "StandardName" SG_ 1278 cell43 "Kraken_TsacCellboard5Temperature_cell43_degC";
BA_ "StandardName" SG_ 1278 cell38 "Kraken_TsacCellboard5Temperature_cell38_degC";
BA_ "StandardName" SG_ 1278 cell33 "Kraken_TsacCellboard5Temperature_cell33_degC";
BA_ "StandardName" SG_ 1278 cell28 "Kraken_TsacCellboard5Temperature_cell28_degC";
BA_ "StandardName" SG_ 1278 cell23 "Kraken_TsacCellboard5Temperature_cell23_degC";
BA_ "StandardName" SG_ 1278 cell18 "Kraken_TsacCellboard5Temperature_cell18_degC";
BA_ "StandardName" SG_ 1278 cell13 "Kraken_TsacCellboard5Temperature_cell13_degC";
BA_ "StandardName" SG_ 1278 cell8 "Kraken_TsacCellboard5Temperature_cell8_degC";
BA_ "StandardName" SG_ 1278 cell3 "Kraken_TsacCellboard5Temperature_cell3_degC";
BA_ "StandardName" SG_ 1278 cell47 "Kraken_TsacCellboard5Temperature_cell47_degC";
BA_ "StandardName" SG_ 1278 cell42 "Kraken_TsacCellboard5Temperature_cell42_degC";
BA_ "StandardName" SG_ 1278 cell37 "Kraken_TsacCellboard5Temperature_cell37_degC";
BA_ "StandardName" SG_ 1278 cell32 "Kraken_TsacCellboard5Temperature_cell32_degC";
BA_ "StandardName" SG_ 1278 cell27 "Kraken_TsacCellboard5Temperature_cell27_degC";
BA_ "StandardName" SG_ 1278 cell22 "Kraken_TsacCellboard5Temperature_cell22_degC";
BA_ "StandardName" SG_ 1278 cell17 "Kraken_TsacCellboard5Temperature_cell17_degC";
BA_ "StandardName" SG_ 1278 cell12 "Kraken_TsacCellboard5Temperature_cell12_degC";
BA_ "StandardName" SG_ 1278 cell7 "Kraken_TsacCellboard5Temperature_cell7_degC";
BA_ "StandardName" SG_ 1278 cell2 "Kraken_TsacCellboard5Temperature_cell2_degC";
BA_ "StandardName" SG_ 1278 cell46 "Kraken_TsacCellboard5Temperature_cell46_degC";
BA_ "StandardName" SG_ 1278 cell41 "Kraken_TsacCellboard5Temperature_cell41_degC";
BA_ "StandardName" SG_ 1278 cell36 "Kraken_TsacCellboard5Temperature_cell36_degC";
BA_ "StandardName" SG_ 1278 cell31 "Kraken_TsacCellboard5Temperature_cell31_degC";
BA_ "StandardName" SG_ 1278 cell26 "Kraken_TsacCellboard5Temperature_cell26_degC";
BA_ "StandardName" SG_ 1278 cell21 "Kraken_TsacCellboard5Temperature_cell21_degC";
BA_ "StandardName" SG_ 1278 cell16 "Kraken_TsacCellboard5Temperature_cell16_degC";
BA_ "StandardName" SG_ 1278 cell11 "Kraken_TsacCellboard5Temperature_cell11_degC";
BA_ "StandardName" SG_ 1278 cell6 "Kraken_TsacCellboard5Temperature_cell6_degC";
BA_ "StandardName" SG_ 1278 cell1 "Kraken_TsacCellboard5Temperature_cell1_degC";
BA_ "StandardName" SG_ 1279 cell45 "Kraken_TsacCellboard6Temperature_cell45_degC";
BA_ "StandardName" SG_ 1279 cell40 "Kraken_TsacCellboard6Temperature_cell40_degC";
BA_ "StandardName" SG_ 1279 cell35 "Kraken_TsacCellboard6Temperature_cell35_degC";
BA_ "StandardName" SG_ 1279 cell30 "Kraken_TsacCellboard6Temperature_cell30_degC";
BA_ "StandardName" SG_ 1279 cell25 "Kraken_TsacCellboard6Temperature_cell25_degC";
BA_ "StandardName" SG_ 1279 cell20 "Kraken_TsacCellboard6Temperature_cell20_degC";
BA_ "StandardName" SG_ 1279 cell15 "Kraken_TsacCellboard6Temperature_cell15_degC";
BA_ "StandardName" SG_ 1279 cell10 "Kraken_TsacCellboard6Temperature_cell10_degC";
BA_ "StandardName" SG_ 1279 cell5 "Kraken_TsacCellboard6Temperature_cell5_degC";
BA_ "StandardName" SG_ 1279 cell44 "Kraken_TsacCellboard6Temperature_cell44_degC";
BA_ "StandardName" SG_ 1279 cell39 "Kraken_TsacCellboard6Temperature_cell39_degC";
BA_ "StandardName" SG_ 1279 cell34 "Kraken_TsacCellboard6Temperature_cell34_degC";
BA_ "StandardName" SG_ 1279 cell29 "Kraken_TsacCellboard6Temperature_cell29_degC";
BA_ "StandardName" SG_ 1279 cell24 "Kraken_TsacCellboard6Temperature_cell24_degC";
BA_ "StandardName" SG_ 1279 cell19 "Kraken_TsacCellboard6Temperature_cell19_degC";
BA_ "StandardName" SG_ 1279 cell14 "Kraken_TsacCellboard6Temperature_cell14_degC";
BA_ "StandardName" SG_ 1279 cell9 "Kraken_TsacCellboard6Temperature_cell9_degC";
BA_ "StandardName" SG_ 1279 cell4 "Kraken_TsacCellboard6Temperature_cell4_degC";
BA_ "StandardName" SG_ 1279 cell48 "Kraken_TsacCellboard6Temperature_cell48_degC";
BA_ "StandardName" SG_ 1279 cell43 "Kraken_TsacCellboard6Temperature_cell43_degC";
BA_ "StandardName" SG_ 1279 cell38 "Kraken_TsacCellboard6Temperature_cell38_degC";
BA_ "StandardName" SG_ 1279 cell33 "Kraken_TsacCellboard6Temperature_cell33_degC";
BA_ "StandardName" SG_ 1279 cell28 "Kraken_TsacCellboard6Temperature_cell28_degC";
BA_ "StandardName" SG_ 1279 cell23 "Kraken_TsacCellboard6Temperature_cell23_degC";
BA_ "StandardName" SG_ 1279 cell18 "Kraken_TsacCellboard6Temperature_cell18_degC";
BA_ "StandardName" SG_ 1279 cell13 "Kraken_TsacCellboard6Temperature_cell13_degC";
BA_ "StandardName" SG_ 1279 cell8 "Kraken_TsacCellboard6Temperature_cell8_degC";
BA_ "StandardName" SG_ 1279 cell3 "Kraken_TsacCellboard6Temperature_cell3_degC";
BA_ "StandardName" SG_ 1279 cell47 "Kraken_TsacCellboard6Temperature_cell47_degC";
BA_ "StandardName" SG_ 1279 cell42 "Kraken_TsacCellboard6Temperature_cell42_degC";
BA_ "StandardName" SG_ 1279 cell37 "Kraken_TsacCellboard6Temperature_cell37_degC";
BA_ "StandardName" SG_ 1279 cell32 "Kraken_TsacCellboard6Temperature_cell32_degC";
BA_ "StandardName" SG_ 1279 cell27 "Kraken_TsacCellboard6Temperature_cell27_degC";
BA_ "StandardName" SG_ 1279 cell22 "Kraken_TsacCellboard6Temperature_cell22_degC";
BA_ "StandardName" SG_ 1279 cell17 "Kraken_TsacCellboard6Temperature_cell17_degC";
BA_ "StandardName" SG_ 1279 cell12 "Kraken_TsacCellboard6Temperature_cell12_degC";
BA_ "StandardName" SG_ 1279 cell7 "Kraken_TsacCellboard6Temperature_cell7_degC";
BA_ "StandardName" SG_ 1279 cell2 "Kraken_TsacCellboard6Temperature_cell2_degC";
BA_ "StandardName" SG_ 1279 cell46 "Kraken_TsacCellboard6Temperature_cell46_degC";
BA_ "StandardName" SG_ 1279 cell41 "Kraken_TsacCellboard6Temperature_cell41_degC";
BA_ "StandardName" SG_ 1279 cell36 "Kraken_TsacCellboard6Temperature_cell36_degC";
BA_ "StandardName" SG_ 1279 cell31 "Kraken_TsacCellboard6Temperature_cell31_degC";
BA_ "StandardName" SG_ 1279 cell26 "Kraken_TsacCellboard6Temperature_cell26_degC";
BA_ "StandardName" SG_ 1279 cell21 "Kraken_TsacCellboard6Temperature_cell21_degC";
BA_ "StandardName" SG_ 1279 cell16 "Kraken_TsacCellboard6Temperature_cell16_degC";
BA_ "StandardName" SG_ 1279 cell11 "Kraken_TsacCellboard6Temperature_cell11_degC";
BA_ "StandardName" SG_ 1279 cell6 "Kraken_TsacCellboard6Temperature_cell6_degC";
BA_ "StandardName" SG_ 1279 cell1 "Kraken_TsacCellboard6Temperature_cell1_degC";
BA_ "StandardName" SG_ 1280 outlet3 "Kraken_TsacMainboardTemperatureCooling_outlet3_degC";
BA_ "StandardName" SG_ 1280 outlet2 "Kraken_TsacMainboardTemperatureCooling_outlet2_degC";
BA_ "StandardName" SG_ 1280 outlet1 "Kraken_TsacMainboardTemperatureCooling_outlet1_degC";
BA_ "StandardName" SG_ 1280 inlet "Kraken_TsacMainboardTemperatureCooling_inlet_degC";
BA_ "StandardName" SG_ 1281 outlet6 "Kraken_TsacMainboardTemperatureCooling_outlet6_degC";
BA_ "StandardName" SG_ 1281 outlet5 "Kraken_TsacMainboardTemperatureCooling_outlet5_degC";
BA_ "StandardName" SG_ 1281 outlet4 "Kraken_TsacMainboardTemperatureCooling_outlet4_degC";
BA_ "SystemMessageLongSymbol" BO_ 1282 "TsacCellboard1BalancingTemperature";
BA_ "GenMsgCycleTime" BO_ 1282 500;
BA_ "StandardName" SG_ 1282 dischargeResistor5 "Kraken_TsacCellboard1Temperature_dischargeResistor5_degC";
BA_ "StandardName" SG_ 1282 dischargeResistor4 "Kraken_TsacCellboard1Temperature_dischargeResistor4_degC";
BA_ "StandardName" SG_ 1282 dischargeResistor3 "Kraken_TsacCellboard1Temperature_dischargeResistor3_degC";
BA_ "StandardName" SG_ 1282 dischargeResistor2 "Kraken_TsacCellboard1Temperature_dischargeResistor2_degC";
BA_ "StandardName" SG_ 1282 dischargeResistor1 "Kraken_TsacCellboard1Temperature_dischargeResistor1_degC";
BA_ "SystemMessageLongSymbol" BO_ 1283 "TsacCellboard2BalancingTemperature";
BA_ "GenMsgCycleTime" BO_ 1283 500;
BA_ "StandardName" SG_ 1283 dischargeResistor5 "Kraken_TsacCellboard2Temperature_dischargeResistor5_degC";
BA_ "StandardName" SG_ 1283 dischargeResistor4 "Kraken_TsacCellboard2Temperature_dischargeResistor4_degC";
BA_ "StandardName" SG_ 1283 dischargeResistor3 "Kraken_TsacCellboard2Temperature_dischargeResistor3_degC";
BA_ "StandardName" SG_ 1283 dischargeResistor2 "Kraken_TsacCellboard2Temperature_dischargeResistor2_degC";
BA_ "StandardName" SG_ 1283 dischargeResistor1 "Kraken_TsacCellboard2Temperature_dischargeResistor1_degC";
BA_ "SystemMessageLongSymbol" BO_ 1284 "TsacCellboard3BalancingTemperature";
BA_ "GenMsgCycleTime" BO_ 1284 500;
BA_ "StandardName" SG_ 1284 dischargeResistor5 "Kraken_TsacCellboard3Temperature_dischargeResistor5_degC";
BA_ "StandardName" SG_ 1284 dischargeResistor4 "Kraken_TsacCellboard3Temperature_dischargeResistor4_degC";
BA_ "StandardName" SG_ 1284 dischargeResistor3 "Kraken_TsacCellboard3Temperature_dischargeResistor3_degC";
BA_ "StandardName" SG_ 1284 dischargeResistor2 "Kraken_TsacCellboard3Temperature_dischargeResistor2_degC";
BA_ "StandardName" SG_ 1284 dischargeResistor1 "Kraken_TsacCellboard3Temperature_dischargeResistor1_degC";
BA_ "SystemMessageLongSymbol" BO_ 1285 "TsacCellboard4BalancingTemperature";
BA_ "GenMsgCycleTime" BO_ 1285 500;
BA_ "StandardName" SG_ 1285 dischargeResistor5 "Kraken_TsacCellboard4Temperature_dischargeResistor5_degC";
BA_ "StandardName" SG_ 1285 dischargeResistor4 "Kraken_TsacCellboard4Temperature_dischargeResistor4_degC";
BA_ "StandardName" SG_ 1285 dischargeResistor3 "Kraken_TsacCellboard4Temperature_dischargeResistor3_degC";
BA_ "StandardName" SG_ 1285 dischargeResistor2 "Kraken_TsacCellboard4Temperature_dischargeResistor2_degC";
BA_ "StandardName" SG_ 1285 dischargeResistor1 "Kraken_TsacCellboard4Temperature_dischargeResistor1_degC";
BA_ "SystemMessageLongSymbol" BO_ 1286 "TsacCellboard5BalancingTemperature";
BA_ "GenMsgCycleTime" BO_ 1286 500;
BA_ "StandardName" SG_ 1286 dischargeResistor5 "Kraken_TsacCellboard5Temperature_dischargeResistor5_degC";
BA_ "StandardName" SG_ 1286 dischargeResistor4 "Kraken_TsacCellboard5Temperature_dischargeResistor4_degC";
BA_ "StandardName" SG_ 1286 dischargeResistor3 "Kraken_TsacCellboard5Temperature_dischargeResistor3_degC";
BA_ "StandardName" SG_ 1286 dischargeResistor2 "Kraken_TsacCellboard5Temperature_dischargeResistor2_degC";
BA_ "StandardName" SG_ 1286 dischargeResistor1 "Kraken_TsacCellboard5Temperature_dischargeResistor1_degC";
BA_ "SystemMessageLongSymbol" BO_ 1287 "TsacCellboard6BalancingTemperature";
BA_ "GenMsgCycleTime" BO_ 1287 500;
BA_ "StandardName" SG_ 1287 dischargeResistor5 "Kraken_TsacCellboard6Temperature_dischargeResistor5_degC";
BA_ "StandardName" SG_ 1287 dischargeResistor4 "Kraken_TsacCellboard6Temperature_dischargeResistor4_degC";
BA_ "StandardName" SG_ 1287 dischargeResistor3 "Kraken_TsacCellboard6Temperature_dischargeResistor3_degC";
BA_ "StandardName" SG_ 1287 dischargeResistor2 "Kraken_TsacCellboard6Temperature_dischargeResistor2_degC";
BA_ "StandardName" SG_ 1287 dischargeResistor1 "Kraken_TsacCellboard6Temperature_dischargeResistor1_degC";
BA_ "StandardName" SG_ 1288 cell24 "Kraken_TsacCellboard1Balancing_cell24_bool";
BA_ "SignalTypeName" SG_ 1288 cell24 "bool";
BA_ "SignalType" SG_ 1288 cell24 "bool";
BA_ "Bitfield" SG_ 1288 cell24 "true";
BA_ "StandardName" SG_ 1288 cell23 "Kraken_TsacCellboard1Balancing_cell23_bool";
BA_ "SignalTypeName" SG_ 1288 cell23 "bool";
BA_ "SignalType" SG_ 1288 cell23 "bool";
BA_ "Bitfield" SG_ 1288 cell23 "true";
BA_ "StandardName" SG_ 1288 cell22 "Kraken_TsacCellboard1Balancing_cell22_bool";
BA_ "SignalTypeName" SG_ 1288 cell22 "bool";
BA_ "SignalType" SG_ 1288 cell22 "bool";
BA_ "Bitfield" SG_ 1288 cell22 "true";
BA_ "StandardName" SG_ 1288 cell21 "Kraken_TsacCellboard1Balancing_cell21_bool";
BA_ "SignalTypeName" SG_ 1288 cell21 "bool";
BA_ "SignalType" SG_ 1288 cell21 "bool";
BA_ "Bitfield" SG_ 1288 cell21 "true";
BA_ "StandardName" SG_ 1288 cell20 "Kraken_TsacCellboard1Balancing_cell20_bool";
BA_ "SignalTypeName" SG_ 1288 cell20 "bool";
BA_ "SignalType" SG_ 1288 cell20 "bool";
BA_ "Bitfield" SG_ 1288 cell20 "true";
BA_ "StandardName" SG_ 1288 cell19 "Kraken_TsacCellboard1Balancing_cell19_bool";
BA_ "SignalTypeName" SG_ 1288 cell19 "bool";
BA_ "SignalType" SG_ 1288 cell19 "bool";
BA_ "Bitfield" SG_ 1288 cell19 "true";
BA_ "StandardName" SG_ 1288 cell18 "Kraken_TsacCellboard1Balancing_cell18_bool";
BA_ "SignalTypeName" SG_ 1288 cell18 "bool";
BA_ "SignalType" SG_ 1288 cell18 "bool";
BA_ "Bitfield" SG_ 1288 cell18 "true";
BA_ "StandardName" SG_ 1288 cell17 "Kraken_TsacCellboard1Balancing_cell17_bool";
BA_ "SignalTypeName" SG_ 1288 cell17 "bool";
BA_ "SignalType" SG_ 1288 cell17 "bool";
BA_ "Bitfield" SG_ 1288 cell17 "true";
BA_ "StandardName" SG_ 1288 cell16 "Kraken_TsacCellboard1Balancing_cell16_bool";
BA_ "SignalTypeName" SG_ 1288 cell16 "bool";
BA_ "SignalType" SG_ 1288 cell16 "bool";
BA_ "Bitfield" SG_ 1288 cell16 "true";
BA_ "StandardName" SG_ 1288 cell15 "Kraken_TsacCellboard1Balancing_cell15_bool";
BA_ "SignalTypeName" SG_ 1288 cell15 "bool";
BA_ "SignalType" SG_ 1288 cell15 "bool";
BA_ "Bitfield" SG_ 1288 cell15 "true";
BA_ "StandardName" SG_ 1288 cell14 "Kraken_TsacCellboard1Balancing_cell14_bool";
BA_ "SignalTypeName" SG_ 1288 cell14 "bool";
BA_ "SignalType" SG_ 1288 cell14 "bool";
BA_ "Bitfield" SG_ 1288 cell14 "true";
BA_ "StandardName" SG_ 1288 cell13 "Kraken_TsacCellboard1Balancing_cell13_bool";
BA_ "SignalTypeName" SG_ 1288 cell13 "bool";
BA_ "SignalType" SG_ 1288 cell13 "bool";
BA_ "Bitfield" SG_ 1288 cell13 "true";
BA_ "StandardName" SG_ 1288 cell12 "Kraken_TsacCellboard1Balancing_cell12_bool";
BA_ "SignalTypeName" SG_ 1288 cell12 "bool";
BA_ "SignalType" SG_ 1288 cell12 "bool";
BA_ "Bitfield" SG_ 1288 cell12 "true";
BA_ "StandardName" SG_ 1288 cell11 "Kraken_TsacCellboard1Balancing_cell11_bool";
BA_ "SignalTypeName" SG_ 1288 cell11 "bool";
BA_ "SignalType" SG_ 1288 cell11 "bool";
BA_ "Bitfield" SG_ 1288 cell11 "true";
BA_ "StandardName" SG_ 1288 cell10 "Kraken_TsacCellboard1Balancing_cell10_bool";
BA_ "SignalTypeName" SG_ 1288 cell10 "bool";
BA_ "SignalType" SG_ 1288 cell10 "bool";
BA_ "Bitfield" SG_ 1288 cell10 "true";
BA_ "StandardName" SG_ 1288 cell9 "Kraken_TsacCellboard1Balancing_cell9_bool";
BA_ "SignalTypeName" SG_ 1288 cell9 "bool";
BA_ "SignalType" SG_ 1288 cell9 "bool";
BA_ "Bitfield" SG_ 1288 cell9 "true";
BA_ "StandardName" SG_ 1288 cell8 "Kraken_TsacCellboard1Balancing_cell8_bool";
BA_ "SignalTypeName" SG_ 1288 cell8 "bool";
BA_ "SignalType" SG_ 1288 cell8 "bool";
BA_ "Bitfield" SG_ 1288 cell8 "true";
BA_ "StandardName" SG_ 1288 cell7 "Kraken_TsacCellboard1Balancing_cell7_bool";
BA_ "SignalTypeName" SG_ 1288 cell7 "bool";
BA_ "SignalType" SG_ 1288 cell7 "bool";
BA_ "Bitfield" SG_ 1288 cell7 "true";
BA_ "StandardName" SG_ 1288 cell6 "Kraken_TsacCellboard1Balancing_cell6_bool";
BA_ "SignalTypeName" SG_ 1288 cell6 "bool";
BA_ "SignalType" SG_ 1288 cell6 "bool";
BA_ "Bitfield" SG_ 1288 cell6 "true";
BA_ "StandardName" SG_ 1288 cell5 "Kraken_TsacCellboard1Balancing_cell5_bool";
BA_ "SignalTypeName" SG_ 1288 cell5 "bool";
BA_ "SignalType" SG_ 1288 cell5 "bool";
BA_ "Bitfield" SG_ 1288 cell5 "true";
BA_ "StandardName" SG_ 1288 cell4 "Kraken_TsacCellboard1Balancing_cell4_bool";
BA_ "SignalTypeName" SG_ 1288 cell4 "bool";
BA_ "SignalType" SG_ 1288 cell4 "bool";
BA_ "Bitfield" SG_ 1288 cell4 "true";
BA_ "StandardName" SG_ 1288 cell3 "Kraken_TsacCellboard1Balancing_cell3_bool";
BA_ "SignalTypeName" SG_ 1288 cell3 "bool";
BA_ "SignalType" SG_ 1288 cell3 "bool";
BA_ "Bitfield" SG_ 1288 cell3 "true";
BA_ "StandardName" SG_ 1288 cell2 "Kraken_TsacCellboard1Balancing_cell2_bool";
BA_ "SignalTypeName" SG_ 1288 cell2 "bool";
BA_ "SignalType" SG_ 1288 cell2 "bool";
BA_ "Bitfield" SG_ 1288 cell2 "true";
BA_ "StandardName" SG_ 1288 cell1 "Kraken_TsacCellboard1Balancing_cell1_bool";
BA_ "SignalTypeName" SG_ 1288 cell1 "bool";
BA_ "SignalType" SG_ 1288 cell1 "bool";
BA_ "Bitfield" SG_ 1288 cell1 "true";
BA_ "StandardName" SG_ 1289 cell24 "Kraken_TsacCellboard2Balancing_cell24_bool";
BA_ "SignalTypeName" SG_ 1289 cell24 "bool";
BA_ "SignalType" SG_ 1289 cell24 "bool";
BA_ "Bitfield" SG_ 1289 cell24 "true";
BA_ "StandardName" SG_ 1289 cell23 "Kraken_TsacCellboard2Balancing_cell23_bool";
BA_ "SignalTypeName" SG_ 1289 cell23 "bool";
BA_ "SignalType" SG_ 1289 cell23 "bool";
BA_ "Bitfield" SG_ 1289 cell23 "true";
BA_ "StandardName" SG_ 1289 cell22 "Kraken_TsacCellboard2Balancing_cell22_bool";
BA_ "SignalTypeName" SG_ 1289 cell22 "bool";
BA_ "SignalType" SG_ 1289 cell22 "bool";
BA_ "Bitfield" SG_ 1289 cell22 "true";
BA_ "StandardName" SG_ 1289 cell21 "Kraken_TsacCellboard2Balancing_cell21_bool";
BA_ "SignalTypeName" SG_ 1289 cell21 "bool";
BA_ "SignalType" SG_ 1289 cell21 "bool";
BA_ "Bitfield" SG_ 1289 cell21 "true";
BA_ "StandardName" SG_ 1289 cell20 "Kraken_TsacCellboard2Balancing_cell20_bool";
BA_ "SignalTypeName" SG_ 1289 cell20 "bool";
BA_ "SignalType" SG_ 1289 cell20 "bool";
BA_ "Bitfield" SG_ 1289 cell20 "true";
BA_ "StandardName" SG_ 1289 cell19 "Kraken_TsacCellboard2Balancing_cell19_bool";
BA_ "SignalTypeName" SG_ 1289 cell19 "bool";
BA_ "SignalType" SG_ 1289 cell19 "bool";
BA_ "Bitfield" SG_ 1289 cell19 "true";
BA_ "StandardName" SG_ 1289 cell18 "Kraken_TsacCellboard2Balancing_cell18_bool";
BA_ "SignalTypeName" SG_ 1289 cell18 "bool";
BA_ "SignalType" SG_ 1289 cell18 "bool";
BA_ "Bitfield" SG_ 1289 cell18 "true";
BA_ "StandardName" SG_ 1289 cell17 "Kraken_TsacCellboard2Balancing_cell17_bool";
BA_ "SignalTypeName" SG_ 1289 cell17 "bool";
BA_ "SignalType" SG_ 1289 cell17 "bool";
BA_ "Bitfield" SG_ 1289 cell17 "true";
BA_ "StandardName" SG_ 1289 cell16 "Kraken_TsacCellboard2Balancing_cell16_bool";
BA_ "SignalTypeName" SG_ 1289 cell16 "bool";
BA_ "SignalType" SG_ 1289 cell16 "bool";
BA_ "Bitfield" SG_ 1289 cell16 "true";
BA_ "StandardName" SG_ 1289 cell15 "Kraken_TsacCellboard2Balancing_cell15_bool";
BA_ "SignalTypeName" SG_ 1289 cell15 "bool";
BA_ "SignalType" SG_ 1289 cell15 "bool";
BA_ "Bitfield" SG_ 1289 cell15 "true";
BA_ "StandardName" SG_ 1289 cell14 "Kraken_TsacCellboard2Balancing_cell14_bool";
BA_ "SignalTypeName" SG_ 1289 cell14 "bool";
BA_ "SignalType" SG_ 1289 cell14 "bool";
BA_ "Bitfield" SG_ 1289 cell14 "true";
BA_ "StandardName" SG_ 1289 cell13 "Kraken_TsacCellboard2Balancing_cell13_bool";
BA_ "SignalTypeName" SG_ 1289 cell13 "bool";
BA_ "SignalType" SG_ 1289 cell13 "bool";
BA_ "Bitfield" SG_ 1289 cell13 "true";
BA_ "StandardName" SG_ 1289 cell12 "Kraken_TsacCellboard2Balancing_cell12_bool";
BA_ "SignalTypeName" SG_ 1289 cell12 "bool";
BA_ "SignalType" SG_ 1289 cell12 "bool";
BA_ "Bitfield" SG_ 1289 cell12 "true";
BA_ "StandardName" SG_ 1289 cell11 "Kraken_TsacCellboard2Balancing_cell11_bool";
BA_ "SignalTypeName" SG_ 1289 cell11 "bool";
BA_ "SignalType" SG_ 1289 cell11 "bool";
BA_ "Bitfield" SG_ 1289 cell11 "true";
BA_ "StandardName" SG_ 1289 cell10 "Kraken_TsacCellboard2Balancing_cell10_bool";
BA_ "SignalTypeName" SG_ 1289 cell10 "bool";
BA_ "SignalType" SG_ 1289 cell10 "bool";
BA_ "Bitfield" SG_ 1289 cell10 "true";
BA_ "StandardName" SG_ 1289 cell9 "Kraken_TsacCellboard2Balancing_cell9_bool";
BA_ "SignalTypeName" SG_ 1289 cell9 "bool";
BA_ "SignalType" SG_ 1289 cell9 "bool";
BA_ "Bitfield" SG_ 1289 cell9 "true";
BA_ "StandardName" SG_ 1289 cell8 "Kraken_TsacCellboard2Balancing_cell8_bool";
BA_ "SignalTypeName" SG_ 1289 cell8 "bool";
BA_ "SignalType" SG_ 1289 cell8 "bool";
BA_ "Bitfield" SG_ 1289 cell8 "true";
BA_ "StandardName" SG_ 1289 cell7 "Kraken_TsacCellboard2Balancing_cell7_bool";
BA_ "SignalTypeName" SG_ 1289 cell7 "bool";
BA_ "SignalType" SG_ 1289 cell7 "bool";
BA_ "Bitfield" SG_ 1289 cell7 "true";
BA_ "StandardName" SG_ 1289 cell6 "Kraken_TsacCellboard2Balancing_cell6_bool";
BA_ "SignalTypeName" SG_ 1289 cell6 "bool";
BA_ "SignalType" SG_ 1289 cell6 "bool";
BA_ "Bitfield" SG_ 1289 cell6 "true";
BA_ "StandardName" SG_ 1289 cell5 "Kraken_TsacCellboard2Balancing_cell5_bool";
BA_ "SignalTypeName" SG_ 1289 cell5 "bool";
BA_ "SignalType" SG_ 1289 cell5 "bool";
BA_ "Bitfield" SG_ 1289 cell5 "true";
BA_ "StandardName" SG_ 1289 cell4 "Kraken_TsacCellboard2Balancing_cell4_bool";
BA_ "SignalTypeName" SG_ 1289 cell4 "bool";
BA_ "SignalType" SG_ 1289 cell4 "bool";
BA_ "Bitfield" SG_ 1289 cell4 "true";
BA_ "StandardName" SG_ 1289 cell3 "Kraken_TsacCellboard2Balancing_cell3_bool";
BA_ "SignalTypeName" SG_ 1289 cell3 "bool";
BA_ "SignalType" SG_ 1289 cell3 "bool";
BA_ "Bitfield" SG_ 1289 cell3 "true";
BA_ "StandardName" SG_ 1289 cell2 "Kraken_TsacCellboard2Balancing_cell2_bool";
BA_ "SignalTypeName" SG_ 1289 cell2 "bool";
BA_ "SignalType" SG_ 1289 cell2 "bool";
BA_ "Bitfield" SG_ 1289 cell2 "true";
BA_ "StandardName" SG_ 1289 cell1 "Kraken_TsacCellboard2Balancing_cell1_bool";
BA_ "SignalTypeName" SG_ 1289 cell1 "bool";
BA_ "SignalType" SG_ 1289 cell1 "bool";
BA_ "Bitfield" SG_ 1289 cell1 "true";
BA_ "StandardName" SG_ 1290 cell24 "Kraken_TsacCellboard3Balancing_cell24_bool";
BA_ "SignalTypeName" SG_ 1290 cell24 "bool";
BA_ "SignalType" SG_ 1290 cell24 "bool";
BA_ "Bitfield" SG_ 1290 cell24 "true";
BA_ "StandardName" SG_ 1290 cell23 "Kraken_TsacCellboard3Balancing_cell23_bool";
BA_ "SignalTypeName" SG_ 1290 cell23 "bool";
BA_ "SignalType" SG_ 1290 cell23 "bool";
BA_ "Bitfield" SG_ 1290 cell23 "true";
BA_ "StandardName" SG_ 1290 cell22 "Kraken_TsacCellboard3Balancing_cell22_bool";
BA_ "SignalTypeName" SG_ 1290 cell22 "bool";
BA_ "SignalType" SG_ 1290 cell22 "bool";
BA_ "Bitfield" SG_ 1290 cell22 "true";
BA_ "StandardName" SG_ 1290 cell21 "Kraken_TsacCellboard3Balancing_cell21_bool";
BA_ "SignalTypeName" SG_ 1290 cell21 "bool";
BA_ "SignalType" SG_ 1290 cell21 "bool";
BA_ "Bitfield" SG_ 1290 cell21 "true";
BA_ "StandardName" SG_ 1290 cell20 "Kraken_TsacCellboard3Balancing_cell20_bool";
BA_ "SignalTypeName" SG_ 1290 cell20 "bool";
BA_ "SignalType" SG_ 1290 cell20 "bool";
BA_ "Bitfield" SG_ 1290 cell20 "true";
BA_ "StandardName" SG_ 1290 cell19 "Kraken_TsacCellboard3Balancing_cell19_bool";
BA_ "SignalTypeName" SG_ 1290 cell19 "bool";
BA_ "SignalType" SG_ 1290 cell19 "bool";
BA_ "Bitfield" SG_ 1290 cell19 "true";
BA_ "StandardName" SG_ 1290 cell18 "Kraken_TsacCellboard3Balancing_cell18_bool";
BA_ "SignalTypeName" SG_ 1290 cell18 "bool";
BA_ "SignalType" SG_ 1290 cell18 "bool";
BA_ "Bitfield" SG_ 1290 cell18 "true";
BA_ "StandardName" SG_ 1290 cell17 "Kraken_TsacCellboard3Balancing_cell17_bool";
BA_ "SignalTypeName" SG_ 1290 cell17 "bool";
BA_ "SignalType" SG_ 1290 cell17 "bool";
BA_ "Bitfield" SG_ 1290 cell17 "true";
BA_ "StandardName" SG_ 1290 cell16 "Kraken_TsacCellboard3Balancing_cell16_bool";
BA_ "SignalTypeName" SG_ 1290 cell16 "bool";
BA_ "SignalType" SG_ 1290 cell16 "bool";
BA_ "Bitfield" SG_ 1290 cell16 "true";
BA_ "StandardName" SG_ 1290 cell15 "Kraken_TsacCellboard3Balancing_cell15_bool";
BA_ "SignalTypeName" SG_ 1290 cell15 "bool";
BA_ "SignalType" SG_ 1290 cell15 "bool";
BA_ "Bitfield" SG_ 1290 cell15 "true";
BA_ "StandardName" SG_ 1290 cell14 "Kraken_TsacCellboard3Balancing_cell14_bool";
BA_ "SignalTypeName" SG_ 1290 cell14 "bool";
BA_ "SignalType" SG_ 1290 cell14 "bool";
BA_ "Bitfield" SG_ 1290 cell14 "true";
BA_ "StandardName" SG_ 1290 cell13 "Kraken_TsacCellboard3Balancing_cell13_bool";
BA_ "SignalTypeName" SG_ 1290 cell13 "bool";
BA_ "SignalType" SG_ 1290 cell13 "bool";
BA_ "Bitfield" SG_ 1290 cell13 "true";
BA_ "StandardName" SG_ 1290 cell12 "Kraken_TsacCellboard3Balancing_cell12_bool";
BA_ "SignalTypeName" SG_ 1290 cell12 "bool";
BA_ "SignalType" SG_ 1290 cell12 "bool";
BA_ "Bitfield" SG_ 1290 cell12 "true";
BA_ "StandardName" SG_ 1290 cell11 "Kraken_TsacCellboard3Balancing_cell11_bool";
BA_ "SignalTypeName" SG_ 1290 cell11 "bool";
BA_ "SignalType" SG_ 1290 cell11 "bool";
BA_ "Bitfield" SG_ 1290 cell11 "true";
BA_ "StandardName" SG_ 1290 cell10 "Kraken_TsacCellboard3Balancing_cell10_bool";
BA_ "SignalTypeName" SG_ 1290 cell10 "bool";
BA_ "SignalType" SG_ 1290 cell10 "bool";
BA_ "Bitfield" SG_ 1290 cell10 "true";
BA_ "StandardName" SG_ 1290 cell9 "Kraken_TsacCellboard3Balancing_cell9_bool";
BA_ "SignalTypeName" SG_ 1290 cell9 "bool";
BA_ "SignalType" SG_ 1290 cell9 "bool";
BA_ "Bitfield" SG_ 1290 cell9 "true";
BA_ "StandardName" SG_ 1290 cell8 "Kraken_TsacCellboard3Balancing_cell8_bool";
BA_ "SignalTypeName" SG_ 1290 cell8 "bool";
BA_ "SignalType" SG_ 1290 cell8 "bool";
BA_ "Bitfield" SG_ 1290 cell8 "true";
BA_ "StandardName" SG_ 1290 cell7 "Kraken_TsacCellboard3Balancing_cell7_bool";
BA_ "SignalTypeName" SG_ 1290 cell7 "bool";
BA_ "SignalType" SG_ 1290 cell7 "bool";
BA_ "Bitfield" SG_ 1290 cell7 "true";
BA_ "StandardName" SG_ 1290 cell6 "Kraken_TsacCellboard3Balancing_cell6_bool";
BA_ "SignalTypeName" SG_ 1290 cell6 "bool";
BA_ "SignalType" SG_ 1290 cell6 "bool";
BA_ "Bitfield" SG_ 1290 cell6 "true";
BA_ "StandardName" SG_ 1290 cell5 "Kraken_TsacCellboard3Balancing_cell5_bool";
BA_ "SignalTypeName" SG_ 1290 cell5 "bool";
BA_ "SignalType" SG_ 1290 cell5 "bool";
BA_ "Bitfield" SG_ 1290 cell5 "true";
BA_ "StandardName" SG_ 1290 cell4 "Kraken_TsacCellboard3Balancing_cell4_bool";
BA_ "SignalTypeName" SG_ 1290 cell4 "bool";
BA_ "SignalType" SG_ 1290 cell4 "bool";
BA_ "Bitfield" SG_ 1290 cell4 "true";
BA_ "StandardName" SG_ 1290 cell3 "Kraken_TsacCellboard3Balancing_cell3_bool";
BA_ "SignalTypeName" SG_ 1290 cell3 "bool";
BA_ "SignalType" SG_ 1290 cell3 "bool";
BA_ "Bitfield" SG_ 1290 cell3 "true";
BA_ "StandardName" SG_ 1290 cell2 "Kraken_TsacCellboard3Balancing_cell2_bool";
BA_ "SignalTypeName" SG_ 1290 cell2 "bool";
BA_ "SignalType" SG_ 1290 cell2 "bool";
BA_ "Bitfield" SG_ 1290 cell2 "true";
BA_ "StandardName" SG_ 1290 cell1 "Kraken_TsacCellboard3Balancing_cell1_bool";
BA_ "SignalTypeName" SG_ 1290 cell1 "bool";
BA_ "SignalType" SG_ 1290 cell1 "bool";
BA_ "Bitfield" SG_ 1290 cell1 "true";
BA_ "StandardName" SG_ 1291 cell24 "Kraken_TsacCellboard4Balancing_cell24_bool";
BA_ "SignalTypeName" SG_ 1291 cell24 "bool";
BA_ "SignalType" SG_ 1291 cell24 "bool";
BA_ "Bitfield" SG_ 1291 cell24 "true";
BA_ "StandardName" SG_ 1291 cell23 "Kraken_TsacCellboard4Balancing_cell23_bool";
BA_ "SignalTypeName" SG_ 1291 cell23 "bool";
BA_ "SignalType" SG_ 1291 cell23 "bool";
BA_ "Bitfield" SG_ 1291 cell23 "true";
BA_ "StandardName" SG_ 1291 cell22 "Kraken_TsacCellboard4Balancing_cell22_bool";
BA_ "SignalTypeName" SG_ 1291 cell22 "bool";
BA_ "SignalType" SG_ 1291 cell22 "bool";
BA_ "Bitfield" SG_ 1291 cell22 "true";
BA_ "StandardName" SG_ 1291 cell21 "Kraken_TsacCellboard4Balancing_cell21_bool";
BA_ "SignalTypeName" SG_ 1291 cell21 "bool";
BA_ "SignalType" SG_ 1291 cell21 "bool";
BA_ "Bitfield" SG_ 1291 cell21 "true";
BA_ "StandardName" SG_ 1291 cell20 "Kraken_TsacCellboard4Balancing_cell20_bool";
BA_ "SignalTypeName" SG_ 1291 cell20 "bool";
BA_ "SignalType" SG_ 1291 cell20 "bool";
BA_ "Bitfield" SG_ 1291 cell20 "true";
BA_ "StandardName" SG_ 1291 cell19 "Kraken_TsacCellboard4Balancing_cell19_bool";
BA_ "SignalTypeName" SG_ 1291 cell19 "bool";
BA_ "SignalType" SG_ 1291 cell19 "bool";
BA_ "Bitfield" SG_ 1291 cell19 "true";
BA_ "StandardName" SG_ 1291 cell18 "Kraken_TsacCellboard4Balancing_cell18_bool";
BA_ "SignalTypeName" SG_ 1291 cell18 "bool";
BA_ "SignalType" SG_ 1291 cell18 "bool";
BA_ "Bitfield" SG_ 1291 cell18 "true";
BA_ "StandardName" SG_ 1291 cell17 "Kraken_TsacCellboard4Balancing_cell17_bool";
BA_ "SignalTypeName" SG_ 1291 cell17 "bool";
BA_ "SignalType" SG_ 1291 cell17 "bool";
BA_ "Bitfield" SG_ 1291 cell17 "true";
BA_ "StandardName" SG_ 1291 cell16 "Kraken_TsacCellboard4Balancing_cell16_bool";
BA_ "SignalTypeName" SG_ 1291 cell16 "bool";
BA_ "SignalType" SG_ 1291 cell16 "bool";
BA_ "Bitfield" SG_ 1291 cell16 "true";
BA_ "StandardName" SG_ 1291 cell15 "Kraken_TsacCellboard4Balancing_cell15_bool";
BA_ "SignalTypeName" SG_ 1291 cell15 "bool";
BA_ "SignalType" SG_ 1291 cell15 "bool";
BA_ "Bitfield" SG_ 1291 cell15 "true";
BA_ "StandardName" SG_ 1291 cell14 "Kraken_TsacCellboard4Balancing_cell14_bool";
BA_ "SignalTypeName" SG_ 1291 cell14 "bool";
BA_ "SignalType" SG_ 1291 cell14 "bool";
BA_ "Bitfield" SG_ 1291 cell14 "true";
BA_ "StandardName" SG_ 1291 cell13 "Kraken_TsacCellboard4Balancing_cell13_bool";
BA_ "SignalTypeName" SG_ 1291 cell13 "bool";
BA_ "SignalType" SG_ 1291 cell13 "bool";
BA_ "Bitfield" SG_ 1291 cell13 "true";
BA_ "StandardName" SG_ 1291 cell12 "Kraken_TsacCellboard4Balancing_cell12_bool";
BA_ "SignalTypeName" SG_ 1291 cell12 "bool";
BA_ "SignalType" SG_ 1291 cell12 "bool";
BA_ "Bitfield" SG_ 1291 cell12 "true";
BA_ "StandardName" SG_ 1291 cell11 "Kraken_TsacCellboard4Balancing_cell11_bool";
BA_ "SignalTypeName" SG_ 1291 cell11 "bool";
BA_ "SignalType" SG_ 1291 cell11 "bool";
BA_ "Bitfield" SG_ 1291 cell11 "true";
BA_ "StandardName" SG_ 1291 cell10 "Kraken_TsacCellboard4Balancing_cell10_bool";
BA_ "SignalTypeName" SG_ 1291 cell10 "bool";
BA_ "SignalType" SG_ 1291 cell10 "bool";
BA_ "Bitfield" SG_ 1291 cell10 "true";
BA_ "StandardName" SG_ 1291 cell9 "Kraken_TsacCellboard4Balancing_cell9_bool";
BA_ "SignalTypeName" SG_ 1291 cell9 "bool";
BA_ "SignalType" SG_ 1291 cell9 "bool";
BA_ "Bitfield" SG_ 1291 cell9 "true";
BA_ "StandardName" SG_ 1291 cell8 "Kraken_TsacCellboard4Balancing_cell8_bool";
BA_ "SignalTypeName" SG_ 1291 cell8 "bool";
BA_ "SignalType" SG_ 1291 cell8 "bool";
BA_ "Bitfield" SG_ 1291 cell8 "true";
BA_ "StandardName" SG_ 1291 cell7 "Kraken_TsacCellboard4Balancing_cell7_bool";
BA_ "SignalTypeName" SG_ 1291 cell7 "bool";
BA_ "SignalType" SG_ 1291 cell7 "bool";
BA_ "Bitfield" SG_ 1291 cell7 "true";
BA_ "StandardName" SG_ 1291 cell6 "Kraken_TsacCellboard4Balancing_cell6_bool";
BA_ "SignalTypeName" SG_ 1291 cell6 "bool";
BA_ "SignalType" SG_ 1291 cell6 "bool";
BA_ "Bitfield" SG_ 1291 cell6 "true";
BA_ "StandardName" SG_ 1291 cell5 "Kraken_TsacCellboard4Balancing_cell5_bool";
BA_ "SignalTypeName" SG_ 1291 cell5 "bool";
BA_ "SignalType" SG_ 1291 cell5 "bool";
BA_ "Bitfield" SG_ 1291 cell5 "true";
BA_ "StandardName" SG_ 1291 cell4 "Kraken_TsacCellboard4Balancing_cell4_bool";
BA_ "SignalTypeName" SG_ 1291 cell4 "bool";
BA_ "SignalType" SG_ 1291 cell4 "bool";
BA_ "Bitfield" SG_ 1291 cell4 "true";
BA_ "StandardName" SG_ 1291 cell3 "Kraken_TsacCellboard4Balancing_cell3_bool";
BA_ "SignalTypeName" SG_ 1291 cell3 "bool";
BA_ "SignalType" SG_ 1291 cell3 "bool";
BA_ "Bitfield" SG_ 1291 cell3 "true";
BA_ "StandardName" SG_ 1291 cell2 "Kraken_TsacCellboard4Balancing_cell2_bool";
BA_ "SignalTypeName" SG_ 1291 cell2 "bool";
BA_ "SignalType" SG_ 1291 cell2 "bool";
BA_ "Bitfield" SG_ 1291 cell2 "true";
BA_ "StandardName" SG_ 1291 cell1 "Kraken_TsacCellboard4Balancing_cell1_bool";
BA_ "SignalTypeName" SG_ 1291 cell1 "bool";
BA_ "SignalType" SG_ 1291 cell1 "bool";
BA_ "Bitfield" SG_ 1291 cell1 "true";
BA_ "StandardName" SG_ 1292 cell24 "Kraken_TsacCellboard5Balancing_cell24_bool";
BA_ "SignalTypeName" SG_ 1292 cell24 "bool";
BA_ "SignalType" SG_ 1292 cell24 "bool";
BA_ "Bitfield" SG_ 1292 cell24 "true";
BA_ "StandardName" SG_ 1292 cell23 "Kraken_TsacCellboard5Balancing_cell23_bool";
BA_ "SignalTypeName" SG_ 1292 cell23 "bool";
BA_ "SignalType" SG_ 1292 cell23 "bool";
BA_ "Bitfield" SG_ 1292 cell23 "true";
BA_ "StandardName" SG_ 1292 cell22 "Kraken_TsacCellboard5Balancing_cell22_bool";
BA_ "SignalTypeName" SG_ 1292 cell22 "bool";
BA_ "SignalType" SG_ 1292 cell22 "bool";
BA_ "Bitfield" SG_ 1292 cell22 "true";
BA_ "StandardName" SG_ 1292 cell21 "Kraken_TsacCellboard5Balancing_cell21_bool";
BA_ "SignalTypeName" SG_ 1292 cell21 "bool";
BA_ "SignalType" SG_ 1292 cell21 "bool";
BA_ "Bitfield" SG_ 1292 cell21 "true";
BA_ "StandardName" SG_ 1292 cell20 "Kraken_TsacCellboard5Balancing_cell20_bool";
BA_ "SignalTypeName" SG_ 1292 cell20 "bool";
BA_ "SignalType" SG_ 1292 cell20 "bool";
BA_ "Bitfield" SG_ 1292 cell20 "true";
BA_ "StandardName" SG_ 1292 cell19 "Kraken_TsacCellboard5Balancing_cell19_bool";
BA_ "SignalTypeName" SG_ 1292 cell19 "bool";
BA_ "SignalType" SG_ 1292 cell19 "bool";
BA_ "Bitfield" SG_ 1292 cell19 "true";
BA_ "StandardName" SG_ 1292 cell18 "Kraken_TsacCellboard5Balancing_cell18_bool";
BA_ "SignalTypeName" SG_ 1292 cell18 "bool";
BA_ "SignalType" SG_ 1292 cell18 "bool";
BA_ "Bitfield" SG_ 1292 cell18 "true";
BA_ "StandardName" SG_ 1292 cell17 "Kraken_TsacCellboard5Balancing_cell17_bool";
BA_ "SignalTypeName" SG_ 1292 cell17 "bool";
BA_ "SignalType" SG_ 1292 cell17 "bool";
BA_ "Bitfield" SG_ 1292 cell17 "true";
BA_ "StandardName" SG_ 1292 cell16 "Kraken_TsacCellboard5Balancing_cell16_bool";
BA_ "SignalTypeName" SG_ 1292 cell16 "bool";
BA_ "SignalType" SG_ 1292 cell16 "bool";
BA_ "Bitfield" SG_ 1292 cell16 "true";
BA_ "StandardName" SG_ 1292 cell15 "Kraken_TsacCellboard5Balancing_cell15_bool";
BA_ "SignalTypeName" SG_ 1292 cell15 "bool";
BA_ "SignalType" SG_ 1292 cell15 "bool";
BA_ "Bitfield" SG_ 1292 cell15 "true";
BA_ "StandardName" SG_ 1292 cell14 "Kraken_TsacCellboard5Balancing_cell14_bool";
BA_ "SignalTypeName" SG_ 1292 cell14 "bool";
BA_ "SignalType" SG_ 1292 cell14 "bool";
BA_ "Bitfield" SG_ 1292 cell14 "true";
BA_ "StandardName" SG_ 1292 cell13 "Kraken_TsacCellboard5Balancing_cell13_bool";
BA_ "SignalTypeName" SG_ 1292 cell13 "bool";
BA_ "SignalType" SG_ 1292 cell13 "bool";
BA_ "Bitfield" SG_ 1292 cell13 "true";
BA_ "StandardName" SG_ 1292 cell12 "Kraken_TsacCellboard5Balancing_cell12_bool";
BA_ "SignalTypeName" SG_ 1292 cell12 "bool";
BA_ "SignalType" SG_ 1292 cell12 "bool";
BA_ "Bitfield" SG_ 1292 cell12 "true";
BA_ "StandardName" SG_ 1292 cell11 "Kraken_TsacCellboard5Balancing_cell11_bool";
BA_ "SignalTypeName" SG_ 1292 cell11 "bool";
BA_ "SignalType" SG_ 1292 cell11 "bool";
BA_ "Bitfield" SG_ 1292 cell11 "true";
BA_ "StandardName" SG_ 1292 cell10 "Kraken_TsacCellboard5Balancing_cell10_bool";
BA_ "SignalTypeName" SG_ 1292 cell10 "bool";
BA_ "SignalType" SG_ 1292 cell10 "bool";
BA_ "Bitfield" SG_ 1292 cell10 "true";
BA_ "StandardName" SG_ 1292 cell9 "Kraken_TsacCellboard5Balancing_cell9_bool";
BA_ "SignalTypeName" SG_ 1292 cell9 "bool";
BA_ "SignalType" SG_ 1292 cell9 "bool";
BA_ "Bitfield" SG_ 1292 cell9 "true";
BA_ "StandardName" SG_ 1292 cell8 "Kraken_TsacCellboard5Balancing_cell8_bool";
BA_ "SignalTypeName" SG_ 1292 cell8 "bool";
BA_ "SignalType" SG_ 1292 cell8 "bool";
BA_ "Bitfield" SG_ 1292 cell8 "true";
BA_ "StandardName" SG_ 1292 cell7 "Kraken_TsacCellboard5Balancing_cell7_bool";
BA_ "SignalTypeName" SG_ 1292 cell7 "bool";
BA_ "SignalType" SG_ 1292 cell7 "bool";
BA_ "Bitfield" SG_ 1292 cell7 "true";
BA_ "StandardName" SG_ 1292 cell6 "Kraken_TsacCellboard5Balancing_cell6_bool";
BA_ "SignalTypeName" SG_ 1292 cell6 "bool";
BA_ "SignalType" SG_ 1292 cell6 "bool";
BA_ "Bitfield" SG_ 1292 cell6 "true";
BA_ "StandardName" SG_ 1292 cell5 "Kraken_TsacCellboard5Balancing_cell5_bool";
BA_ "SignalTypeName" SG_ 1292 cell5 "bool";
BA_ "SignalType" SG_ 1292 cell5 "bool";
BA_ "Bitfield" SG_ 1292 cell5 "true";
BA_ "StandardName" SG_ 1292 cell4 "Kraken_TsacCellboard5Balancing_cell4_bool";
BA_ "SignalTypeName" SG_ 1292 cell4 "bool";
BA_ "SignalType" SG_ 1292 cell4 "bool";
BA_ "Bitfield" SG_ 1292 cell4 "true";
BA_ "StandardName" SG_ 1292 cell3 "Kraken_TsacCellboard5Balancing_cell3_bool";
BA_ "SignalTypeName" SG_ 1292 cell3 "bool";
BA_ "SignalType" SG_ 1292 cell3 "bool";
BA_ "Bitfield" SG_ 1292 cell3 "true";
BA_ "StandardName" SG_ 1292 cell2 "Kraken_TsacCellboard5Balancing_cell2_bool";
BA_ "SignalTypeName" SG_ 1292 cell2 "bool";
BA_ "SignalType" SG_ 1292 cell2 "bool";
BA_ "Bitfield" SG_ 1292 cell2 "true";
BA_ "StandardName" SG_ 1292 cell1 "Kraken_TsacCellboard5Balancing_cell1_bool";
BA_ "SignalTypeName" SG_ 1292 cell1 "bool";
BA_ "SignalType" SG_ 1292 cell1 "bool";
BA_ "Bitfield" SG_ 1292 cell1 "true";
BA_ "StandardName" SG_ 1293 cell24 "Kraken_TsacCellboard6Balancing_cell24_bool";
BA_ "SignalTypeName" SG_ 1293 cell24 "bool";
BA_ "SignalType" SG_ 1293 cell24 "bool";
BA_ "Bitfield" SG_ 1293 cell24 "true";
BA_ "StandardName" SG_ 1293 cell23 "Kraken_TsacCellboard6Balancing_cell23_bool";
BA_ "SignalTypeName" SG_ 1293 cell23 "bool";
BA_ "SignalType" SG_ 1293 cell23 "bool";
BA_ "Bitfield" SG_ 1293 cell23 "true";
BA_ "StandardName" SG_ 1293 cell22 "Kraken_TsacCellboard6Balancing_cell22_bool";
BA_ "SignalTypeName" SG_ 1293 cell22 "bool";
BA_ "SignalType" SG_ 1293 cell22 "bool";
BA_ "Bitfield" SG_ 1293 cell22 "true";
BA_ "StandardName" SG_ 1293 cell21 "Kraken_TsacCellboard6Balancing_cell21_bool";
BA_ "SignalTypeName" SG_ 1293 cell21 "bool";
BA_ "SignalType" SG_ 1293 cell21 "bool";
BA_ "Bitfield" SG_ 1293 cell21 "true";
BA_ "StandardName" SG_ 1293 cell20 "Kraken_TsacCellboard6Balancing_cell20_bool";
BA_ "SignalTypeName" SG_ 1293 cell20 "bool";
BA_ "SignalType" SG_ 1293 cell20 "bool";
BA_ "Bitfield" SG_ 1293 cell20 "true";
BA_ "StandardName" SG_ 1293 cell19 "Kraken_TsacCellboard6Balancing_cell19_bool";
BA_ "SignalTypeName" SG_ 1293 cell19 "bool";
BA_ "SignalType" SG_ 1293 cell19 "bool";
BA_ "Bitfield" SG_ 1293 cell19 "true";
BA_ "StandardName" SG_ 1293 cell18 "Kraken_TsacCellboard6Balancing_cell18_bool";
BA_ "SignalTypeName" SG_ 1293 cell18 "bool";
BA_ "SignalType" SG_ 1293 cell18 "bool";
BA_ "Bitfield" SG_ 1293 cell18 "true";
BA_ "StandardName" SG_ 1293 cell17 "Kraken_TsacCellboard6Balancing_cell17_bool";
BA_ "SignalTypeName" SG_ 1293 cell17 "bool";
BA_ "SignalType" SG_ 1293 cell17 "bool";
BA_ "Bitfield" SG_ 1293 cell17 "true";
BA_ "StandardName" SG_ 1293 cell16 "Kraken_TsacCellboard6Balancing_cell16_bool";
BA_ "SignalTypeName" SG_ 1293 cell16 "bool";
BA_ "SignalType" SG_ 1293 cell16 "bool";
BA_ "Bitfield" SG_ 1293 cell16 "true";
BA_ "StandardName" SG_ 1293 cell15 "Kraken_TsacCellboard6Balancing_cell15_bool";
BA_ "SignalTypeName" SG_ 1293 cell15 "bool";
BA_ "SignalType" SG_ 1293 cell15 "bool";
BA_ "Bitfield" SG_ 1293 cell15 "true";
BA_ "StandardName" SG_ 1293 cell14 "Kraken_TsacCellboard6Balancing_cell14_bool";
BA_ "SignalTypeName" SG_ 1293 cell14 "bool";
BA_ "SignalType" SG_ 1293 cell14 "bool";
BA_ "Bitfield" SG_ 1293 cell14 "true";
BA_ "StandardName" SG_ 1293 cell13 "Kraken_TsacCellboard6Balancing_cell13_bool";
BA_ "SignalTypeName" SG_ 1293 cell13 "bool";
BA_ "SignalType" SG_ 1293 cell13 "bool";
BA_ "Bitfield" SG_ 1293 cell13 "true";
BA_ "StandardName" SG_ 1293 cell12 "Kraken_TsacCellboard6Balancing_cell12_bool";
BA_ "SignalTypeName" SG_ 1293 cell12 "bool";
BA_ "SignalType" SG_ 1293 cell12 "bool";
BA_ "Bitfield" SG_ 1293 cell12 "true";
BA_ "StandardName" SG_ 1293 cell11 "Kraken_TsacCellboard6Balancing_cell11_bool";
BA_ "SignalTypeName" SG_ 1293 cell11 "bool";
BA_ "SignalType" SG_ 1293 cell11 "bool";
BA_ "Bitfield" SG_ 1293 cell11 "true";
BA_ "StandardName" SG_ 1293 cell10 "Kraken_TsacCellboard6Balancing_cell10_bool";
BA_ "SignalTypeName" SG_ 1293 cell10 "bool";
BA_ "SignalType" SG_ 1293 cell10 "bool";
BA_ "Bitfield" SG_ 1293 cell10 "true";
BA_ "StandardName" SG_ 1293 cell9 "Kraken_TsacCellboard6Balancing_cell9_bool";
BA_ "SignalTypeName" SG_ 1293 cell9 "bool";
BA_ "SignalType" SG_ 1293 cell9 "bool";
BA_ "Bitfield" SG_ 1293 cell9 "true";
BA_ "StandardName" SG_ 1293 cell8 "Kraken_TsacCellboard6Balancing_cell8_bool";
BA_ "SignalTypeName" SG_ 1293 cell8 "bool";
BA_ "SignalType" SG_ 1293 cell8 "bool";
BA_ "Bitfield" SG_ 1293 cell8 "true";
BA_ "StandardName" SG_ 1293 cell7 "Kraken_TsacCellboard6Balancing_cell7_bool";
BA_ "SignalTypeName" SG_ 1293 cell7 "bool";
BA_ "SignalType" SG_ 1293 cell7 "bool";
BA_ "Bitfield" SG_ 1293 cell7 "true";
BA_ "StandardName" SG_ 1293 cell6 "Kraken_TsacCellboard6Balancing_cell6_bool";
BA_ "SignalTypeName" SG_ 1293 cell6 "bool";
BA_ "SignalType" SG_ 1293 cell6 "bool";
BA_ "Bitfield" SG_ 1293 cell6 "true";
BA_ "StandardName" SG_ 1293 cell5 "Kraken_TsacCellboard6Balancing_cell5_bool";
BA_ "SignalTypeName" SG_ 1293 cell5 "bool";
BA_ "SignalType" SG_ 1293 cell5 "bool";
BA_ "Bitfield" SG_ 1293 cell5 "true";
BA_ "StandardName" SG_ 1293 cell4 "Kraken_TsacCellboard6Balancing_cell4_bool";
BA_ "SignalTypeName" SG_ 1293 cell4 "bool";
BA_ "SignalType" SG_ 1293 cell4 "bool";
BA_ "Bitfield" SG_ 1293 cell4 "true";
BA_ "StandardName" SG_ 1293 cell3 "Kraken_TsacCellboard6Balancing_cell3_bool";
BA_ "SignalTypeName" SG_ 1293 cell3 "bool";
BA_ "SignalType" SG_ 1293 cell3 "bool";
BA_ "Bitfield" SG_ 1293 cell3 "true";
BA_ "StandardName" SG_ 1293 cell2 "Kraken_TsacCellboard6Balancing_cell2_bool";
BA_ "SignalTypeName" SG_ 1293 cell2 "bool";
BA_ "SignalType" SG_ 1293 cell2 "bool";
BA_ "Bitfield" SG_ 1293 cell2 "true";
BA_ "StandardName" SG_ 1293 cell1 "Kraken_TsacCellboard6Balancing_cell1_bool";
BA_ "SignalTypeName" SG_ 1293 cell1 "bool";
BA_ "SignalType" SG_ 1293 cell1 "bool";
BA_ "Bitfield" SG_ 1293 cell1 "true";
BA_ "StandardName" SG_ 415 ok "Kraken_TsacMainboardImd_ok_bool";
BA_ "SignalTypeName" SG_ 415 ok "bool";
BA_ "SignalType" SG_ 415 ok "bool";
BA_ "StandardName" SG_ 415 dutyCycle "Kraken_TsacMainboardImd_dutyCycle_U";
BA_ "StandardName" SG_ 415 frequency "Kraken_TsacMainboardImd_frequency_Hz";
BA_ "StandardName" SG_ 415 status "Kraken_TsacMainboardImd_status_enum";
BA_ "SignalTypeName" SG_ 415 status "TsacMainboardImdStatus";
BA_ "SignalType" SG_ 415 status "enum";
BA_ "StandardName" SG_ 416 prechargeVoltage "ShutDown_Precharge_voltage_V";
BA_ "StandardName" SG_ 416 airpVoltage "ShutDown_AirP_voltage_V";
BA_ "StandardName" SG_ 416 airnVoltage "ShutDown_AirN_voltage_V";
BA_ "StandardName" SG_ 416 imdVoltage "ShutDown_Imd_voltage_V";
BA_ "StandardName" SG_ 416 imdStatus "ShutDown_Imd_status_enum";
BA_ "SignalTypeName" SG_ 416 imdStatus "TsacMainboardImdStatus";
BA_ "SignalType" SG_ 416 imdStatus "enum";
BA_ "StandardName" SG_ 416 amsVoltage "ShutDown_Ams_voltage_V";
BA_ "StandardName" SG_ 416 interlockTsacVoltage "ShutDown_InterlockTsac_voltage_V";
BA_ "StandardName" SG_ 1294 tsalGreen "Kraken_TsacMainboardFeedback_tsalGreen_V";
BA_ "StandardName" SG_ 1294 extFaultCockpitLed "Kraken_TsacMainboardFeedback_extFaultCockpitLed_bool";
BA_ "Bitfield" SG_ 1294 extFaultCockpitLed "true";
BA_ "StandardName" SG_ 1294 imdFaultCockpitLed "Kraken_TsacMainboardFeedback_imdFaultCockpitLed_bool";
BA_ "Bitfield" SG_ 1294 imdFaultCockpitLed "true";
BA_ "StandardName" SG_ 1294 bmsFaultCockpitLed "Kraken_TsacMainboardFeedback_bmsFaultCockpitLed_bool";
BA_ "Bitfield" SG_ 1294 bmsFaultCockpitLed "true";
BA_ "StandardName" SG_ 1294 plausibleStateRc "Kraken_TsacMainboardFeedback_plausibleStateRc_V";
BA_ "StandardName" SG_ 1294 plausibleState "Kraken_TsacMainboardFeedback_plausibleState_bool";
BA_ "Bitfield" SG_ 1294 plausibleState "true";
BA_ "StandardName" SG_ 1294 plausibleStatePersisted "Kraken_TsacMainboardFeedback_plausibleStatePersisted_bool";
BA_ "Bitfield" SG_ 1294 plausibleStatePersisted "true";
BA_ "StandardName" SG_ 1294 plausibleStateLatched "Kraken_TsacMainboardFeedback_plausibleStateLatched_bool";
BA_ "Bitfield" SG_ 1294 plausibleStateLatched "true";
BA_ "StandardName" SG_ 1294 tsLessThan60V "Kraken_TsacMainboardFeedback_tsLessThan60V_bool";
BA_ "Bitfield" SG_ 1294 tsLessThan60V "true";
BA_ "StandardName" SG_ 1294 airpOpenMec "Kraken_TsacMainboardFeedback_airpOpenMec_V";
BA_ "StandardName" SG_ 1294 prechargeOpenMec "Kraken_TsacMainboardFeedback_prechargeOpenMec_bool";
BA_ "Bitfield" SG_ 1294 prechargeOpenMec "true";
BA_ "StandardName" SG_ 1294 airnOpenMec "Kraken_TsacMainboardFeedback_airnOpenMec_V";
BA_ "StandardName" SG_ 1294 airpOpenCom "Kraken_TsacMainboardFeedback_airpOpenCom_bool";
BA_ "Bitfield" SG_ 1294 airpOpenCom "true";
BA_ "StandardName" SG_ 1294 prechargeOpenCom "Kraken_TsacMainboardFeedback_prechargeOpenCom_bool";
BA_ "Bitfield" SG_ 1294 prechargeOpenCom "true";
BA_ "StandardName" SG_ 1294 airnOpenCom "Kraken_TsacMainboardFeedback_airnOpenCom_bool";
BA_ "Bitfield" SG_ 1294 airnOpenCom "true";
BA_ "StandardName" SG_ 417 sdEnd "Kraken_TsacMainboardFeedback_sdEnd_V";
BA_ "StandardName" SG_ 417 sdIn "Kraken_TsacMainboardFeedback_sdIn_V";
BA_ "StandardName" SG_ 418 imd "Kraken_TsacMainboardError_imd_bool";
BA_ "SignalTypeName" SG_ 418 imd "bool";
BA_ "SignalType" SG_ 418 imd "bool";
BA_ "Bitfield" SG_ 418 imd "true";
BA_ "StandardName" SG_ 418 connectorDisconnected "Kraken_TsacMainboardError_connectorDisconnected_bool";
BA_ "SignalTypeName" SG_ 418 connectorDisconnected "bool";
BA_ "SignalType" SG_ 418 connectorDisconnected "bool";
BA_ "Bitfield" SG_ 418 connectorDisconnected "true";
BA_ "StandardName" SG_ 418 cellboard "Kraken_TsacMainboardError_cellboard_bool";
BA_ "SignalTypeName" SG_ 418 cellboard "bool";
BA_ "SignalType" SG_ 418 cellboard "bool";
BA_ "Bitfield" SG_ 418 cellboard "true";
BA_ "StandardName" SG_ 418 coolingOvertemperature "Kraken_TsacMainboardError_coolingOvertemperature_bool";
BA_ "SignalTypeName" SG_ 418 coolingOvertemperature "bool";
BA_ "SignalType" SG_ 418 coolingOvertemperature "bool";
BA_ "Bitfield" SG_ 418 coolingOvertemperature "true";
BA_ "StandardName" SG_ 418 coolingUndertemperature "Kraken_TsacMainboardError_coolingUndertemperature_bool";
BA_ "SignalTypeName" SG_ 418 coolingUndertemperature "bool";
BA_ "SignalType" SG_ 418 coolingUndertemperature "bool";
BA_ "Bitfield" SG_ 418 coolingUndertemperature "true";
BA_ "StandardName" SG_ 418 currentSensorCommunication "Kraken_TsacMainboardError_currentSensorCommunication_bool";
BA_ "SignalTypeName" SG_ 418 currentSensorCommunication "bool";
BA_ "SignalType" SG_ 418 currentSensorCommunication "bool";
BA_ "Bitfield" SG_ 418 currentSensorCommunication "true";
BA_ "StandardName" SG_ 418 canCommunication "Kraken_TsacMainboardError_canCommunication_bool";
BA_ "SignalTypeName" SG_ 418 canCommunication "bool";
BA_ "SignalType" SG_ 418 canCommunication "bool";
BA_ "Bitfield" SG_ 418 canCommunication "true";
BA_ "StandardName" SG_ 418 overtemperature "Kraken_TsacMainboardError_overtemperature_bool";
BA_ "SignalTypeName" SG_ 418 overtemperature "bool";
BA_ "SignalType" SG_ 418 overtemperature "bool";
BA_ "Bitfield" SG_ 418 overtemperature "true";
BA_ "StandardName" SG_ 418 undertemperature "Kraken_TsacMainboardError_undertemperature_bool";
BA_ "SignalTypeName" SG_ 418 undertemperature "bool";
BA_ "SignalType" SG_ 418 undertemperature "bool";
BA_ "Bitfield" SG_ 418 undertemperature "true";
BA_ "StandardName" SG_ 418 overvoltage "Kraken_TsacMainboardError_overvoltage_bool";
BA_ "SignalTypeName" SG_ 418 overvoltage "bool";
BA_ "SignalType" SG_ 418 overvoltage "bool";
BA_ "Bitfield" SG_ 418 overvoltage "true";
BA_ "StandardName" SG_ 418 undervoltage "Kraken_TsacMainboardError_undervoltage_bool";
BA_ "SignalTypeName" SG_ 418 undervoltage "bool";
BA_ "SignalType" SG_ 418 undervoltage "bool";
BA_ "Bitfield" SG_ 418 undervoltage "true";
BA_ "StandardName" SG_ 418 overpower "Kraken_TsacMainboardError_overpower_bool";
BA_ "SignalTypeName" SG_ 418 overpower "bool";
BA_ "SignalType" SG_ 418 overpower "bool";
BA_ "Bitfield" SG_ 418 overpower "true";
BA_ "StandardName" SG_ 418 overcurrent "Kraken_TsacMainboardError_overcurrent_bool";
BA_ "SignalTypeName" SG_ 418 overcurrent "bool";
BA_ "SignalType" SG_ 418 overcurrent "bool";
BA_ "Bitfield" SG_ 418 overcurrent "true";
BA_ "StandardName" SG_ 418 post "Kraken_TsacMainboardError_post_bool";
BA_ "SignalTypeName" SG_ 418 post "bool";
BA_ "SignalType" SG_ 418 post "bool";
BA_ "Bitfield" SG_ 418 post "true";
BA_ "StandardName" SG_ 419 cellboard2OpenWire13 "Kraken_TsacCellboard2Error_openWire13_bool";
BA_ "SignalTypeName" SG_ 419 cellboard2OpenWire13 "bool";
BA_ "SignalType" SG_ 419 cellboard2OpenWire13 "bool";
BA_ "Bitfield" SG_ 419 cellboard2OpenWire13 "true";
BA_ "StandardName" SG_ 419 cellboard2OpenWire12 "Kraken_TsacCellboard2Error_openWire12_bool";
BA_ "SignalTypeName" SG_ 419 cellboard2OpenWire12 "bool";
BA_ "SignalType" SG_ 419 cellboard2OpenWire12 "bool";
BA_ "Bitfield" SG_ 419 cellboard2OpenWire12 "true";
BA_ "StandardName" SG_ 419 cellboard2OpenWire11 "Kraken_TsacCellboard2Error_openWire11_bool";
BA_ "SignalTypeName" SG_ 419 cellboard2OpenWire11 "bool";
BA_ "SignalType" SG_ 419 cellboard2OpenWire11 "bool";
BA_ "Bitfield" SG_ 419 cellboard2OpenWire11 "true";
BA_ "StandardName" SG_ 419 cellboard2OpenWire10 "Kraken_TsacCellboard2Error_openWire10_bool";
BA_ "SignalTypeName" SG_ 419 cellboard2OpenWire10 "bool";
BA_ "SignalType" SG_ 419 cellboard2OpenWire10 "bool";
BA_ "Bitfield" SG_ 419 cellboard2OpenWire10 "true";
BA_ "StandardName" SG_ 419 cellboard2OpenWire9 "Kraken_TsacCellboard2Error_openWire9_bool";
BA_ "SignalTypeName" SG_ 419 cellboard2OpenWire9 "bool";
BA_ "SignalType" SG_ 419 cellboard2OpenWire9 "bool";
BA_ "Bitfield" SG_ 419 cellboard2OpenWire9 "true";
BA_ "StandardName" SG_ 419 cellboard2OpenWire8 "Kraken_TsacCellboard2Error_openWire8_bool";
BA_ "SignalTypeName" SG_ 419 cellboard2OpenWire8 "bool";
BA_ "SignalType" SG_ 419 cellboard2OpenWire8 "bool";
BA_ "Bitfield" SG_ 419 cellboard2OpenWire8 "true";
BA_ "StandardName" SG_ 419 cellboard2OpenWire7 "Kraken_TsacCellboard2Error_openWire7_bool";
BA_ "SignalTypeName" SG_ 419 cellboard2OpenWire7 "bool";
BA_ "SignalType" SG_ 419 cellboard2OpenWire7 "bool";
BA_ "Bitfield" SG_ 419 cellboard2OpenWire7 "true";
BA_ "StandardName" SG_ 419 cellboard2OpenWire6 "Kraken_TsacCellboard2Error_openWire6_bool";
BA_ "SignalTypeName" SG_ 419 cellboard2OpenWire6 "bool";
BA_ "SignalType" SG_ 419 cellboard2OpenWire6 "bool";
BA_ "Bitfield" SG_ 419 cellboard2OpenWire6 "true";
BA_ "StandardName" SG_ 419 cellboard2OpenWire5 "Kraken_TsacCellboard2Error_openWire5_bool";
BA_ "SignalTypeName" SG_ 419 cellboard2OpenWire5 "bool";
BA_ "SignalType" SG_ 419 cellboard2OpenWire5 "bool";
BA_ "Bitfield" SG_ 419 cellboard2OpenWire5 "true";
BA_ "StandardName" SG_ 419 cellboard2OpenWire4 "Kraken_TsacCellboard2Error_openWire4_bool";
BA_ "SignalTypeName" SG_ 419 cellboard2OpenWire4 "bool";
BA_ "SignalType" SG_ 419 cellboard2OpenWire4 "bool";
BA_ "Bitfield" SG_ 419 cellboard2OpenWire4 "true";
BA_ "StandardName" SG_ 419 cellboard2OpenWire3 "Kraken_TsacCellboard2Error_openWire3_bool";
BA_ "SignalTypeName" SG_ 419 cellboard2OpenWire3 "bool";
BA_ "SignalType" SG_ 419 cellboard2OpenWire3 "bool";
BA_ "Bitfield" SG_ 419 cellboard2OpenWire3 "true";
BA_ "StandardName" SG_ 419 cellboard2OpenWire2 "Kraken_TsacCellboard2Error_openWire2_bool";
BA_ "SignalTypeName" SG_ 419 cellboard2OpenWire2 "bool";
BA_ "SignalType" SG_ 419 cellboard2OpenWire2 "bool";
BA_ "Bitfield" SG_ 419 cellboard2OpenWire2 "true";
BA_ "StandardName" SG_ 419 cellboard2OpenWire1 "Kraken_TsacCellboard2Error_openWire1_bool";
BA_ "SignalTypeName" SG_ 419 cellboard2OpenWire1 "bool";
BA_ "SignalType" SG_ 419 cellboard2OpenWire1 "bool";
BA_ "Bitfield" SG_ 419 cellboard2OpenWire1 "true";
BA_ "StandardName" SG_ 419 cellboard2BmsMonitorCommunicatio "Kraken_TsacCellboard2Error_bmsMonitorCommunication_bool";
BA_ "SignalTypeName" SG_ 419 cellboard2BmsMonitorCommunicatio "bool";
BA_ "SignalType" SG_ 419 cellboard2BmsMonitorCommunicatio "bool";
BA_ "Bitfield" SG_ 419 cellboard2BmsMonitorCommunicatio "true";
BA_ "SystemSignalLongSymbol" SG_ 419 cellboard2BmsMonitorCommunicatio "cellboard2BmsMonitorCommunication";
BA_ "StandardName" SG_ 419 cellboard2Flash "Kraken_TsacCellboard2Error_flash_bool";
BA_ "SignalTypeName" SG_ 419 cellboard2Flash "bool";
BA_ "SignalType" SG_ 419 cellboard2Flash "bool";
BA_ "Bitfield" SG_ 419 cellboard2Flash "true";
BA_ "StandardName" SG_ 419 cellboard2CanCommunication "Kraken_TsacCellboard2Error_canCommunication_bool";
BA_ "SignalTypeName" SG_ 419 cellboard2CanCommunication "bool";
BA_ "SignalType" SG_ 419 cellboard2CanCommunication "bool";
BA_ "Bitfield" SG_ 419 cellboard2CanCommunication "true";
BA_ "StandardName" SG_ 419 cellboard2DischargeResistorOvert "Kraken_TsacCellboard2Error_dischargeResistorOvertemperature_bool";
BA_ "SignalTypeName" SG_ 419 cellboard2DischargeResistorOvert "bool";
BA_ "SignalType" SG_ 419 cellboard2DischargeResistorOvert "bool";
BA_ "Bitfield" SG_ 419 cellboard2DischargeResistorOvert "true";
BA_ "SystemSignalLongSymbol" SG_ 419 cellboard2DischargeResistorOvert "cellboard2DischargeResistorOvertemperature";
BA_ "StandardName" SG_ 419 cellboard2DischargeResistorUnder "Kraken_TsacCellboard2Error_dischargeResistorUndertemperature_bool";
BA_ "SignalTypeName" SG_ 419 cellboard2DischargeResistorUnder "bool";
BA_ "SignalType" SG_ 419 cellboard2DischargeResistorUnder "bool";
BA_ "Bitfield" SG_ 419 cellboard2DischargeResistorUnder "true";
BA_ "SystemSignalLongSymbol" SG_ 419 cellboard2DischargeResistorUnder "cellboard2DischargeResistorUndertemperature";
BA_ "StandardName" SG_ 419 cellboard2CellOvertemperature "Kraken_TsacCellboard2Error_cellOvertemperature_bool";
BA_ "SignalTypeName" SG_ 419 cellboard2CellOvertemperature "bool";
BA_ "SignalType" SG_ 419 cellboard2CellOvertemperature "bool";
BA_ "Bitfield" SG_ 419 cellboard2CellOvertemperature "true";
BA_ "StandardName" SG_ 419 cellboard2CellUndertemperature "Kraken_TsacCellboard2Error_cellUndertemperature_bool";
BA_ "SignalTypeName" SG_ 419 cellboard2CellUndertemperature "bool";
BA_ "SignalType" SG_ 419 cellboard2CellUndertemperature "bool";
BA_ "Bitfield" SG_ 419 cellboard2CellUndertemperature "true";
BA_ "StandardName" SG_ 419 cellboard2CellOvervoltage "Kraken_TsacCellboard2Error_cellOvervoltage_bool";
BA_ "SignalTypeName" SG_ 419 cellboard2CellOvervoltage "bool";
BA_ "SignalType" SG_ 419 cellboard2CellOvervoltage "bool";
BA_ "Bitfield" SG_ 419 cellboard2CellOvervoltage "true";
BA_ "StandardName" SG_ 419 cellboard2CellUndervoltage "Kraken_TsacCellboard2Error_cellUndervoltage_bool";
BA_ "SignalTypeName" SG_ 419 cellboard2CellUndervoltage "bool";
BA_ "SignalType" SG_ 419 cellboard2CellUndervoltage "bool";
BA_ "Bitfield" SG_ 419 cellboard2CellUndervoltage "true";
BA_ "StandardName" SG_ 419 cellboard2Post "Kraken_TsacCellboard2Error_post_bool";
BA_ "SignalTypeName" SG_ 419 cellboard2Post "bool";
BA_ "SignalType" SG_ 419 cellboard2Post "bool";
BA_ "Bitfield" SG_ 419 cellboard2Post "true";
BA_ "StandardName" SG_ 419 cellboard1OpenWire13 "Kraken_TsacCellboard1Error_openWire13_bool";
BA_ "SignalTypeName" SG_ 419 cellboard1OpenWire13 "bool";
BA_ "SignalType" SG_ 419 cellboard1OpenWire13 "bool";
BA_ "Bitfield" SG_ 419 cellboard1OpenWire13 "true";
BA_ "StandardName" SG_ 419 cellboard1OpenWire12 "Kraken_TsacCellboard1Error_openWire12_bool";
BA_ "SignalTypeName" SG_ 419 cellboard1OpenWire12 "bool";
BA_ "SignalType" SG_ 419 cellboard1OpenWire12 "bool";
BA_ "Bitfield" SG_ 419 cellboard1OpenWire12 "true";
BA_ "StandardName" SG_ 419 cellboard1OpenWire11 "Kraken_TsacCellboard1Error_openWire11_bool";
BA_ "SignalTypeName" SG_ 419 cellboard1OpenWire11 "bool";
BA_ "SignalType" SG_ 419 cellboard1OpenWire11 "bool";
BA_ "Bitfield" SG_ 419 cellboard1OpenWire11 "true";
BA_ "StandardName" SG_ 419 cellboard1OpenWire10 "Kraken_TsacCellboard1Error_openWire10_bool";
BA_ "SignalTypeName" SG_ 419 cellboard1OpenWire10 "bool";
BA_ "SignalType" SG_ 419 cellboard1OpenWire10 "bool";
BA_ "Bitfield" SG_ 419 cellboard1OpenWire10 "true";
BA_ "StandardName" SG_ 419 cellboard1OpenWire9 "Kraken_TsacCellboard1Error_openWire9_bool";
BA_ "SignalTypeName" SG_ 419 cellboard1OpenWire9 "bool";
BA_ "SignalType" SG_ 419 cellboard1OpenWire9 "bool";
BA_ "Bitfield" SG_ 419 cellboard1OpenWire9 "true";
BA_ "StandardName" SG_ 419 cellboard1OpenWire8 "Kraken_TsacCellboard1Error_openWire8_bool";
BA_ "SignalTypeName" SG_ 419 cellboard1OpenWire8 "bool";
BA_ "SignalType" SG_ 419 cellboard1OpenWire8 "bool";
BA_ "Bitfield" SG_ 419 cellboard1OpenWire8 "true";
BA_ "StandardName" SG_ 419 cellboard1OpenWire7 "Kraken_TsacCellboard1Error_openWire7_bool";
BA_ "SignalTypeName" SG_ 419 cellboard1OpenWire7 "bool";
BA_ "SignalType" SG_ 419 cellboard1OpenWire7 "bool";
BA_ "Bitfield" SG_ 419 cellboard1OpenWire7 "true";
BA_ "StandardName" SG_ 419 cellboard1OpenWire6 "Kraken_TsacCellboard1Error_openWire6_bool";
BA_ "SignalTypeName" SG_ 419 cellboard1OpenWire6 "bool";
BA_ "SignalType" SG_ 419 cellboard1OpenWire6 "bool";
BA_ "Bitfield" SG_ 419 cellboard1OpenWire6 "true";
BA_ "StandardName" SG_ 419 cellboard1OpenWire5 "Kraken_TsacCellboard1Error_openWire5_bool";
BA_ "SignalTypeName" SG_ 419 cellboard1OpenWire5 "bool";
BA_ "SignalType" SG_ 419 cellboard1OpenWire5 "bool";
BA_ "Bitfield" SG_ 419 cellboard1OpenWire5 "true";
BA_ "StandardName" SG_ 419 cellboard1OpenWire4 "Kraken_TsacCellboard1Error_openWire4_bool";
BA_ "SignalTypeName" SG_ 419 cellboard1OpenWire4 "bool";
BA_ "SignalType" SG_ 419 cellboard1OpenWire4 "bool";
BA_ "Bitfield" SG_ 419 cellboard1OpenWire4 "true";
BA_ "StandardName" SG_ 419 cellboard1OpenWire3 "Kraken_TsacCellboard1Error_openWire3_bool";
BA_ "SignalTypeName" SG_ 419 cellboard1OpenWire3 "bool";
BA_ "SignalType" SG_ 419 cellboard1OpenWire3 "bool";
BA_ "Bitfield" SG_ 419 cellboard1OpenWire3 "true";
BA_ "StandardName" SG_ 419 cellboard1OpenWire2 "Kraken_TsacCellboard1Error_openWire2_bool";
BA_ "SignalTypeName" SG_ 419 cellboard1OpenWire2 "bool";
BA_ "SignalType" SG_ 419 cellboard1OpenWire2 "bool";
BA_ "Bitfield" SG_ 419 cellboard1OpenWire2 "true";
BA_ "StandardName" SG_ 419 cellboard1OpenWire1 "Kraken_TsacCellboard1Error_openWire1_bool";
BA_ "SignalTypeName" SG_ 419 cellboard1OpenWire1 "bool";
BA_ "SignalType" SG_ 419 cellboard1OpenWire1 "bool";
BA_ "Bitfield" SG_ 419 cellboard1OpenWire1 "true";
BA_ "StandardName" SG_ 419 cellboard1BmsMonitorCommunicatio "Kraken_TsacCellboard1Error_bmsMonitorCommunication_bool";
BA_ "SignalTypeName" SG_ 419 cellboard1BmsMonitorCommunicatio "bool";
BA_ "SignalType" SG_ 419 cellboard1BmsMonitorCommunicatio "bool";
BA_ "Bitfield" SG_ 419 cellboard1BmsMonitorCommunicatio "true";
BA_ "SystemSignalLongSymbol" SG_ 419 cellboard1BmsMonitorCommunicatio "cellboard1BmsMonitorCommunication";
BA_ "StandardName" SG_ 419 cellboard1Flash "Kraken_TsacCellboard1Error_flash_bool";
BA_ "SignalTypeName" SG_ 419 cellboard1Flash "bool";
BA_ "SignalType" SG_ 419 cellboard1Flash "bool";
BA_ "Bitfield" SG_ 419 cellboard1Flash "true";
BA_ "StandardName" SG_ 419 cellboard1CanCommunication "Kraken_TsacCellboard1Error_canCommunication_bool";
BA_ "SignalTypeName" SG_ 419 cellboard1CanCommunication "bool";
BA_ "SignalType" SG_ 419 cellboard1CanCommunication "bool";
BA_ "Bitfield" SG_ 419 cellboard1CanCommunication "true";
BA_ "StandardName" SG_ 419 cellboard1DischargeResistorOvert "Kraken_TsacCellboard1Error_dischargeResistorOvertemperature_bool";
BA_ "SignalTypeName" SG_ 419 cellboard1DischargeResistorOvert "bool";
BA_ "SignalType" SG_ 419 cellboard1DischargeResistorOvert "bool";
BA_ "Bitfield" SG_ 419 cellboard1DischargeResistorOvert "true";
BA_ "SystemSignalLongSymbol" SG_ 419 cellboard1DischargeResistorOvert "cellboard1DischargeResistorOvertemperature";
BA_ "StandardName" SG_ 419 cellboard1DischargeResistorUnder "Kraken_TsacCellboard1Error_dischargeResistorUndertemperature_bool";
BA_ "SignalTypeName" SG_ 419 cellboard1DischargeResistorUnder "bool";
BA_ "SignalType" SG_ 419 cellboard1DischargeResistorUnder "bool";
BA_ "Bitfield" SG_ 419 cellboard1DischargeResistorUnder "true";
BA_ "SystemSignalLongSymbol" SG_ 419 cellboard1DischargeResistorUnder "cellboard1DischargeResistorUndertemperature";
BA_ "StandardName" SG_ 419 cellboard1CellOvertemperature "Kraken_TsacCellboard1Error_cellOvertemperature_bool";
BA_ "SignalTypeName" SG_ 419 cellboard1CellOvertemperature "bool";
BA_ "SignalType" SG_ 419 cellboard1CellOvertemperature "bool";
BA_ "Bitfield" SG_ 419 cellboard1CellOvertemperature "true";
BA_ "StandardName" SG_ 419 cellboard1CellUndertemperature "Kraken_TsacCellboard1Error_cellUndertemperature_bool";
BA_ "SignalTypeName" SG_ 419 cellboard1CellUndertemperature "bool";
BA_ "SignalType" SG_ 419 cellboard1CellUndertemperature "bool";
BA_ "Bitfield" SG_ 419 cellboard1CellUndertemperature "true";
BA_ "StandardName" SG_ 419 cellboard1CellOvervoltage "Kraken_TsacCellboard1Error_cellOvervoltage_bool";
BA_ "SignalTypeName" SG_ 419 cellboard1CellOvervoltage "bool";
BA_ "SignalType" SG_ 419 cellboard1CellOvervoltage "bool";
BA_ "Bitfield" SG_ 419 cellboard1CellOvervoltage "true";
BA_ "StandardName" SG_ 419 cellboard1CellUndervoltage "Kraken_TsacCellboard1Error_cellUndervoltage_bool";
BA_ "SignalTypeName" SG_ 419 cellboard1CellUndervoltage "bool";
BA_ "SignalType" SG_ 419 cellboard1CellUndervoltage "bool";
BA_ "Bitfield" SG_ 419 cellboard1CellUndervoltage "true";
BA_ "StandardName" SG_ 419 cellboard1Post "Kraken_TsacCellboard1Error_post_bool";
BA_ "SignalTypeName" SG_ 419 cellboard1Post "bool";
BA_ "SignalType" SG_ 419 cellboard1Post "bool";
BA_ "Bitfield" SG_ 419 cellboard1Post "true";
BA_ "StandardName" SG_ 420 cellboard4OpenWire13 "Kraken_TsacCellboard4Error_openWire13_bool";
BA_ "SignalTypeName" SG_ 420 cellboard4OpenWire13 "bool";
BA_ "SignalType" SG_ 420 cellboard4OpenWire13 "bool";
BA_ "Bitfield" SG_ 420 cellboard4OpenWire13 "true";
BA_ "StandardName" SG_ 420 cellboard4OpenWire12 "Kraken_TsacCellboard4Error_openWire12_bool";
BA_ "SignalTypeName" SG_ 420 cellboard4OpenWire12 "bool";
BA_ "SignalType" SG_ 420 cellboard4OpenWire12 "bool";
BA_ "Bitfield" SG_ 420 cellboard4OpenWire12 "true";
BA_ "StandardName" SG_ 420 cellboard4OpenWire11 "Kraken_TsacCellboard4Error_openWire11_bool";
BA_ "SignalTypeName" SG_ 420 cellboard4OpenWire11 "bool";
BA_ "SignalType" SG_ 420 cellboard4OpenWire11 "bool";
BA_ "Bitfield" SG_ 420 cellboard4OpenWire11 "true";
BA_ "StandardName" SG_ 420 cellboard4OpenWire10 "Kraken_TsacCellboard4Error_openWire10_bool";
BA_ "SignalTypeName" SG_ 420 cellboard4OpenWire10 "bool";
BA_ "SignalType" SG_ 420 cellboard4OpenWire10 "bool";
BA_ "Bitfield" SG_ 420 cellboard4OpenWire10 "true";
BA_ "StandardName" SG_ 420 cellboard4OpenWire9 "Kraken_TsacCellboard4Error_openWire9_bool";
BA_ "SignalTypeName" SG_ 420 cellboard4OpenWire9 "bool";
BA_ "SignalType" SG_ 420 cellboard4OpenWire9 "bool";
BA_ "Bitfield" SG_ 420 cellboard4OpenWire9 "true";
BA_ "StandardName" SG_ 420 cellboard4OpenWire8 "Kraken_TsacCellboard4Error_openWire8_bool";
BA_ "SignalTypeName" SG_ 420 cellboard4OpenWire8 "bool";
BA_ "SignalType" SG_ 420 cellboard4OpenWire8 "bool";
BA_ "Bitfield" SG_ 420 cellboard4OpenWire8 "true";
BA_ "StandardName" SG_ 420 cellboard4OpenWire7 "Kraken_TsacCellboard4Error_openWire7_bool";
BA_ "SignalTypeName" SG_ 420 cellboard4OpenWire7 "bool";
BA_ "SignalType" SG_ 420 cellboard4OpenWire7 "bool";
BA_ "Bitfield" SG_ 420 cellboard4OpenWire7 "true";
BA_ "StandardName" SG_ 420 cellboard4OpenWire6 "Kraken_TsacCellboard4Error_openWire6_bool";
BA_ "SignalTypeName" SG_ 420 cellboard4OpenWire6 "bool";
BA_ "SignalType" SG_ 420 cellboard4OpenWire6 "bool";
BA_ "Bitfield" SG_ 420 cellboard4OpenWire6 "true";
BA_ "StandardName" SG_ 420 cellboard4OpenWire5 "Kraken_TsacCellboard4Error_openWire5_bool";
BA_ "SignalTypeName" SG_ 420 cellboard4OpenWire5 "bool";
BA_ "SignalType" SG_ 420 cellboard4OpenWire5 "bool";
BA_ "Bitfield" SG_ 420 cellboard4OpenWire5 "true";
BA_ "StandardName" SG_ 420 cellboard4OpenWire4 "Kraken_TsacCellboard4Error_openWire4_bool";
BA_ "SignalTypeName" SG_ 420 cellboard4OpenWire4 "bool";
BA_ "SignalType" SG_ 420 cellboard4OpenWire4 "bool";
BA_ "Bitfield" SG_ 420 cellboard4OpenWire4 "true";
BA_ "StandardName" SG_ 420 cellboard4OpenWire3 "Kraken_TsacCellboard4Error_openWire3_bool";
BA_ "SignalTypeName" SG_ 420 cellboard4OpenWire3 "bool";
BA_ "SignalType" SG_ 420 cellboard4OpenWire3 "bool";
BA_ "Bitfield" SG_ 420 cellboard4OpenWire3 "true";
BA_ "StandardName" SG_ 420 cellboard4OpenWire2 "Kraken_TsacCellboard4Error_openWire2_bool";
BA_ "SignalTypeName" SG_ 420 cellboard4OpenWire2 "bool";
BA_ "SignalType" SG_ 420 cellboard4OpenWire2 "bool";
BA_ "Bitfield" SG_ 420 cellboard4OpenWire2 "true";
BA_ "StandardName" SG_ 420 cellboard4OpenWire1 "Kraken_TsacCellboard4Error_openWire1_bool";
BA_ "SignalTypeName" SG_ 420 cellboard4OpenWire1 "bool";
BA_ "SignalType" SG_ 420 cellboard4OpenWire1 "bool";
BA_ "Bitfield" SG_ 420 cellboard4OpenWire1 "true";
BA_ "StandardName" SG_ 420 cellboard4BmsMonitorCommunicatio "Kraken_TsacCellboard4Error_bmsMonitorCommunication_bool";
BA_ "SignalTypeName" SG_ 420 cellboard4BmsMonitorCommunicatio "bool";
BA_ "SignalType" SG_ 420 cellboard4BmsMonitorCommunicatio "bool";
BA_ "Bitfield" SG_ 420 cellboard4BmsMonitorCommunicatio "true";
BA_ "SystemSignalLongSymbol" SG_ 420 cellboard4BmsMonitorCommunicatio "cellboard4BmsMonitorCommunication";
BA_ "StandardName" SG_ 420 cellboard4Flash "Kraken_TsacCellboard4Error_flash_bool";
BA_ "SignalTypeName" SG_ 420 cellboard4Flash "bool";
BA_ "SignalType" SG_ 420 cellboard4Flash "bool";
BA_ "Bitfield" SG_ 420 cellboard4Flash "true";
BA_ "StandardName" SG_ 420 cellboard4CanCommunication "Kraken_TsacCellboard4Error_canCommunication_bool";
BA_ "SignalTypeName" SG_ 420 cellboard4CanCommunication "bool";
BA_ "SignalType" SG_ 420 cellboard4CanCommunication "bool";
BA_ "Bitfield" SG_ 420 cellboard4CanCommunication "true";
BA_ "StandardName" SG_ 420 cellboard4DischargeResistorOvert "Kraken_TsacCellboard4Error_dischargeResistorOvertemperature_bool";
BA_ "SignalTypeName" SG_ 420 cellboard4DischargeResistorOvert "bool";
BA_ "SignalType" SG_ 420 cellboard4DischargeResistorOvert "bool";
BA_ "Bitfield" SG_ 420 cellboard4DischargeResistorOvert "true";
BA_ "SystemSignalLongSymbol" SG_ 420 cellboard4DischargeResistorOvert "cellboard4DischargeResistorOvertemperature";
BA_ "StandardName" SG_ 420 cellboard4DischargeResistorUnder "Kraken_TsacCellboard4Error_dischargeResistorUndertemperature_bool";
BA_ "SignalTypeName" SG_ 420 cellboard4DischargeResistorUnder "bool";
BA_ "SignalType" SG_ 420 cellboard4DischargeResistorUnder "bool";
BA_ "Bitfield" SG_ 420 cellboard4DischargeResistorUnder "true";
BA_ "SystemSignalLongSymbol" SG_ 420 cellboard4DischargeResistorUnder "cellboard4DischargeResistorUndertemperature";
BA_ "StandardName" SG_ 420 cellboard4CellOvertemperature "Kraken_TsacCellboard4Error_cellOvertemperature_bool";
BA_ "SignalTypeName" SG_ 420 cellboard4CellOvertemperature "bool";
BA_ "SignalType" SG_ 420 cellboard4CellOvertemperature "bool";
BA_ "Bitfield" SG_ 420 cellboard4CellOvertemperature "true";
BA_ "StandardName" SG_ 420 cellboard4CellUndertemperature "Kraken_TsacCellboard4Error_cellUndertemperature_bool";
BA_ "SignalTypeName" SG_ 420 cellboard4CellUndertemperature "bool";
BA_ "SignalType" SG_ 420 cellboard4CellUndertemperature "bool";
BA_ "Bitfield" SG_ 420 cellboard4CellUndertemperature "true";
BA_ "StandardName" SG_ 420 cellboard4CellOvervoltage "Kraken_TsacCellboard4Error_cellOvervoltage_bool";
BA_ "SignalTypeName" SG_ 420 cellboard4CellOvervoltage "bool";
BA_ "SignalType" SG_ 420 cellboard4CellOvervoltage "bool";
BA_ "Bitfield" SG_ 420 cellboard4CellOvervoltage "true";
BA_ "StandardName" SG_ 420 cellboard4CellUndervoltage "Kraken_TsacCellboard4Error_cellUndervoltage_bool";
BA_ "SignalTypeName" SG_ 420 cellboard4CellUndervoltage "bool";
BA_ "SignalType" SG_ 420 cellboard4CellUndervoltage "bool";
BA_ "Bitfield" SG_ 420 cellboard4CellUndervoltage "true";
BA_ "StandardName" SG_ 420 cellboard4Post "Kraken_TsacCellboard3Error_post_bool";
BA_ "SignalTypeName" SG_ 420 cellboard4Post "bool";
BA_ "SignalType" SG_ 420 cellboard4Post "bool";
BA_ "Bitfield" SG_ 420 cellboard4Post "true";
BA_ "StandardName" SG_ 420 cellboard3OpenWire13 "Kraken_TsacCellboard3Error_openWire13_bool";
BA_ "SignalTypeName" SG_ 420 cellboard3OpenWire13 "bool";
BA_ "SignalType" SG_ 420 cellboard3OpenWire13 "bool";
BA_ "Bitfield" SG_ 420 cellboard3OpenWire13 "true";
BA_ "StandardName" SG_ 420 cellboard3OpenWire12 "Kraken_TsacCellboard3Error_openWire12_bool";
BA_ "SignalTypeName" SG_ 420 cellboard3OpenWire12 "bool";
BA_ "SignalType" SG_ 420 cellboard3OpenWire12 "bool";
BA_ "Bitfield" SG_ 420 cellboard3OpenWire12 "true";
BA_ "StandardName" SG_ 420 cellboard3OpenWire11 "Kraken_TsacCellboard3Error_openWire11_bool";
BA_ "SignalTypeName" SG_ 420 cellboard3OpenWire11 "bool";
BA_ "SignalType" SG_ 420 cellboard3OpenWire11 "bool";
BA_ "Bitfield" SG_ 420 cellboard3OpenWire11 "true";
BA_ "StandardName" SG_ 420 cellboard3OpenWire10 "Kraken_TsacCellboard3Error_openWire10_bool";
BA_ "SignalTypeName" SG_ 420 cellboard3OpenWire10 "bool";
BA_ "SignalType" SG_ 420 cellboard3OpenWire10 "bool";
BA_ "Bitfield" SG_ 420 cellboard3OpenWire10 "true";
BA_ "StandardName" SG_ 420 cellboard3OpenWire9 "Kraken_TsacCellboard3Error_openWire9_bool";
BA_ "SignalTypeName" SG_ 420 cellboard3OpenWire9 "bool";
BA_ "SignalType" SG_ 420 cellboard3OpenWire9 "bool";
BA_ "Bitfield" SG_ 420 cellboard3OpenWire9 "true";
BA_ "StandardName" SG_ 420 cellboard3OpenWire8 "Kraken_TsacCellboard3Error_openWire8_bool";
BA_ "SignalTypeName" SG_ 420 cellboard3OpenWire8 "bool";
BA_ "SignalType" SG_ 420 cellboard3OpenWire8 "bool";
BA_ "Bitfield" SG_ 420 cellboard3OpenWire8 "true";
BA_ "StandardName" SG_ 420 cellboard3OpenWire7 "Kraken_TsacCellboard3Error_openWire7_bool";
BA_ "SignalTypeName" SG_ 420 cellboard3OpenWire7 "bool";
BA_ "SignalType" SG_ 420 cellboard3OpenWire7 "bool";
BA_ "Bitfield" SG_ 420 cellboard3OpenWire7 "true";
BA_ "StandardName" SG_ 420 cellboard3OpenWire6 "Kraken_TsacCellboard3Error_openWire6_bool";
BA_ "SignalTypeName" SG_ 420 cellboard3OpenWire6 "bool";
BA_ "SignalType" SG_ 420 cellboard3OpenWire6 "bool";
BA_ "Bitfield" SG_ 420 cellboard3OpenWire6 "true";
BA_ "StandardName" SG_ 420 cellboard3OpenWire5 "Kraken_TsacCellboard3Error_openWire5_bool";
BA_ "SignalTypeName" SG_ 420 cellboard3OpenWire5 "bool";
BA_ "SignalType" SG_ 420 cellboard3OpenWire5 "bool";
BA_ "Bitfield" SG_ 420 cellboard3OpenWire5 "true";
BA_ "StandardName" SG_ 420 cellboard3OpenWire4 "Kraken_TsacCellboard3Error_openWire4_bool";
BA_ "SignalTypeName" SG_ 420 cellboard3OpenWire4 "bool";
BA_ "SignalType" SG_ 420 cellboard3OpenWire4 "bool";
BA_ "Bitfield" SG_ 420 cellboard3OpenWire4 "true";
BA_ "StandardName" SG_ 420 cellboard3OpenWire3 "Kraken_TsacCellboard3Error_openWire3_bool";
BA_ "SignalTypeName" SG_ 420 cellboard3OpenWire3 "bool";
BA_ "SignalType" SG_ 420 cellboard3OpenWire3 "bool";
BA_ "Bitfield" SG_ 420 cellboard3OpenWire3 "true";
BA_ "StandardName" SG_ 420 cellboard3OpenWire2 "Kraken_TsacCellboard3Error_openWire2_bool";
BA_ "SignalTypeName" SG_ 420 cellboard3OpenWire2 "bool";
BA_ "SignalType" SG_ 420 cellboard3OpenWire2 "bool";
BA_ "Bitfield" SG_ 420 cellboard3OpenWire2 "true";
BA_ "StandardName" SG_ 420 cellboard3OpenWire1 "Kraken_TsacCellboard3Error_openWire1_bool";
BA_ "SignalTypeName" SG_ 420 cellboard3OpenWire1 "bool";
BA_ "SignalType" SG_ 420 cellboard3OpenWire1 "bool";
BA_ "Bitfield" SG_ 420 cellboard3OpenWire1 "true";
BA_ "StandardName" SG_ 420 cellboard3BmsMonitorCommunicatio "Kraken_TsacCellboard3Error_bmsMonitorCommunication_bool";
BA_ "SignalTypeName" SG_ 420 cellboard3BmsMonitorCommunicatio "bool";
BA_ "SignalType" SG_ 420 cellboard3BmsMonitorCommunicatio "bool";
BA_ "Bitfield" SG_ 420 cellboard3BmsMonitorCommunicatio "true";
BA_ "SystemSignalLongSymbol" SG_ 420 cellboard3BmsMonitorCommunicatio "cellboard3BmsMonitorCommunication";
BA_ "StandardName" SG_ 420 cellboard3Flash "Kraken_TsacCellboard3Error_flash_bool";
BA_ "SignalTypeName" SG_ 420 cellboard3Flash "bool";
BA_ "SignalType" SG_ 420 cellboard3Flash "bool";
BA_ "Bitfield" SG_ 420 cellboard3Flash "true";
BA_ "StandardName" SG_ 420 cellboard3CanCommunication "Kraken_TsacCellboard3Error_canCommunication_bool";
BA_ "SignalTypeName" SG_ 420 cellboard3CanCommunication "bool";
BA_ "SignalType" SG_ 420 cellboard3CanCommunication "bool";
BA_ "Bitfield" SG_ 420 cellboard3CanCommunication "true";
BA_ "StandardName" SG_ 420 cellboard3DischargeResistorOvert "Kraken_TsacCellboard3Error_dischargeResistorOvertemperature_bool";
BA_ "SignalTypeName" SG_ 420 cellboard3DischargeResistorOvert "bool";
BA_ "SignalType" SG_ 420 cellboard3DischargeResistorOvert "bool";
BA_ "Bitfield" SG_ 420 cellboard3DischargeResistorOvert "true";
BA_ "SystemSignalLongSymbol" SG_ 420 cellboard3DischargeResistorOvert "cellboard3DischargeResistorOvertemperature";
BA_ "StandardName" SG_ 420 cellboard3DischargeResistorUnder "Kraken_TsacCellboard3Error_dischargeResistorUndertemperature_bool";
BA_ "SignalTypeName" SG_ 420 cellboard3DischargeResistorUnder "bool";
BA_ "SignalType" SG_ 420 cellboard3DischargeResistorUnder "bool";
BA_ "Bitfield" SG_ 420 cellboard3DischargeResistorUnder "true";
BA_ "SystemSignalLongSymbol" SG_ 420 cellboard3DischargeResistorUnder "cellboard3DischargeResistorUndertemperature";
BA_ "StandardName" SG_ 420 cellboard3CellOvertemperature "Kraken_TsacCellboard3Error_cellOvertemperature_bool";
BA_ "SignalTypeName" SG_ 420 cellboard3CellOvertemperature "bool";
BA_ "SignalType" SG_ 420 cellboard3CellOvertemperature "bool";
BA_ "Bitfield" SG_ 420 cellboard3CellOvertemperature "true";
BA_ "StandardName" SG_ 420 cellboard3CellUndertemperature "Kraken_TsacCellboard3Error_cellUndertemperature_bool";
BA_ "SignalTypeName" SG_ 420 cellboard3CellUndertemperature "bool";
BA_ "SignalType" SG_ 420 cellboard3CellUndertemperature "bool";
BA_ "Bitfield" SG_ 420 cellboard3CellUndertemperature "true";
BA_ "StandardName" SG_ 420 cellboard3CellOvervoltage "Kraken_TsacCellboard3Error_cellOvervoltage_bool";
BA_ "SignalTypeName" SG_ 420 cellboard3CellOvervoltage "bool";
BA_ "SignalType" SG_ 420 cellboard3CellOvervoltage "bool";
BA_ "Bitfield" SG_ 420 cellboard3CellOvervoltage "true";
BA_ "StandardName" SG_ 420 cellboard3CellUndervoltage "Kraken_TsacCellboard3Error_cellUndervoltage_bool";
BA_ "SignalTypeName" SG_ 420 cellboard3CellUndervoltage "bool";
BA_ "SignalType" SG_ 420 cellboard3CellUndervoltage "bool";
BA_ "Bitfield" SG_ 420 cellboard3CellUndervoltage "true";
BA_ "StandardName" SG_ 420 cellboard3Post "Kraken_TsacCellboard3Error_post_bool";
BA_ "SignalTypeName" SG_ 420 cellboard3Post "bool";
BA_ "SignalType" SG_ 420 cellboard3Post "bool";
BA_ "Bitfield" SG_ 420 cellboard3Post "true";
BA_ "StandardName" SG_ 421 cellboard6OpenWire13 "Kraken_TsacCellboard6Error_openWire13_bool";
BA_ "SignalTypeName" SG_ 421 cellboard6OpenWire13 "bool";
BA_ "SignalType" SG_ 421 cellboard6OpenWire13 "bool";
BA_ "Bitfield" SG_ 421 cellboard6OpenWire13 "true";
BA_ "StandardName" SG_ 421 cellboard6OpenWire12 "Kraken_TsacCellboard6Error_openWire12_bool";
BA_ "SignalTypeName" SG_ 421 cellboard6OpenWire12 "bool";
BA_ "SignalType" SG_ 421 cellboard6OpenWire12 "bool";
BA_ "Bitfield" SG_ 421 cellboard6OpenWire12 "true";
BA_ "StandardName" SG_ 421 cellboard6OpenWire11 "Kraken_TsacCellboard6Error_openWire11_bool";
BA_ "SignalTypeName" SG_ 421 cellboard6OpenWire11 "bool";
BA_ "SignalType" SG_ 421 cellboard6OpenWire11 "bool";
BA_ "Bitfield" SG_ 421 cellboard6OpenWire11 "true";
BA_ "StandardName" SG_ 421 cellboard6OpenWire10 "Kraken_TsacCellboard6Error_openWire10_bool";
BA_ "SignalTypeName" SG_ 421 cellboard6OpenWire10 "bool";
BA_ "SignalType" SG_ 421 cellboard6OpenWire10 "bool";
BA_ "Bitfield" SG_ 421 cellboard6OpenWire10 "true";
BA_ "StandardName" SG_ 421 cellboard6OpenWire9 "Kraken_TsacCellboard6Error_openWire9_bool";
BA_ "SignalTypeName" SG_ 421 cellboard6OpenWire9 "bool";
BA_ "SignalType" SG_ 421 cellboard6OpenWire9 "bool";
BA_ "Bitfield" SG_ 421 cellboard6OpenWire9 "true";
BA_ "StandardName" SG_ 421 cellboard6OpenWire8 "Kraken_TsacCellboard6Error_openWire8_bool";
BA_ "SignalTypeName" SG_ 421 cellboard6OpenWire8 "bool";
BA_ "SignalType" SG_ 421 cellboard6OpenWire8 "bool";
BA_ "Bitfield" SG_ 421 cellboard6OpenWire8 "true";
BA_ "StandardName" SG_ 421 cellboard6OpenWire7 "Kraken_TsacCellboard6Error_openWire7_bool";
BA_ "SignalTypeName" SG_ 421 cellboard6OpenWire7 "bool";
BA_ "SignalType" SG_ 421 cellboard6OpenWire7 "bool";
BA_ "Bitfield" SG_ 421 cellboard6OpenWire7 "true";
BA_ "StandardName" SG_ 421 cellboard6OpenWire6 "Kraken_TsacCellboard6Error_openWire6_bool";
BA_ "SignalTypeName" SG_ 421 cellboard6OpenWire6 "bool";
BA_ "SignalType" SG_ 421 cellboard6OpenWire6 "bool";
BA_ "Bitfield" SG_ 421 cellboard6OpenWire6 "true";
BA_ "StandardName" SG_ 421 cellboard6OpenWire5 "Kraken_TsacCellboard6Error_openWire5_bool";
BA_ "SignalTypeName" SG_ 421 cellboard6OpenWire5 "bool";
BA_ "SignalType" SG_ 421 cellboard6OpenWire5 "bool";
BA_ "Bitfield" SG_ 421 cellboard6OpenWire5 "true";
BA_ "StandardName" SG_ 421 cellboard6OpenWire4 "Kraken_TsacCellboard6Error_openWire4_bool";
BA_ "SignalTypeName" SG_ 421 cellboard6OpenWire4 "bool";
BA_ "SignalType" SG_ 421 cellboard6OpenWire4 "bool";
BA_ "Bitfield" SG_ 421 cellboard6OpenWire4 "true";
BA_ "StandardName" SG_ 421 cellboard6OpenWire3 "Kraken_TsacCellboard6Error_openWire3_bool";
BA_ "SignalTypeName" SG_ 421 cellboard6OpenWire3 "bool";
BA_ "SignalType" SG_ 421 cellboard6OpenWire3 "bool";
BA_ "Bitfield" SG_ 421 cellboard6OpenWire3 "true";
BA_ "StandardName" SG_ 421 cellboard6OpenWire2 "Kraken_TsacCellboard6Error_openWire2_bool";
BA_ "SignalTypeName" SG_ 421 cellboard6OpenWire2 "bool";
BA_ "SignalType" SG_ 421 cellboard6OpenWire2 "bool";
BA_ "Bitfield" SG_ 421 cellboard6OpenWire2 "true";
BA_ "StandardName" SG_ 421 cellboard6OpenWire1 "Kraken_TsacCellboard6Error_openWire1_bool";
BA_ "SignalTypeName" SG_ 421 cellboard6OpenWire1 "bool";
BA_ "SignalType" SG_ 421 cellboard6OpenWire1 "bool";
BA_ "Bitfield" SG_ 421 cellboard6OpenWire1 "true";
BA_ "StandardName" SG_ 421 cellboard6BmsMonitorCommunicatio "Kraken_TsacCellboard6Error_bmsMonitorCommunication_bool";
BA_ "SignalTypeName" SG_ 421 cellboard6BmsMonitorCommunicatio "bool";
BA_ "SignalType" SG_ 421 cellboard6BmsMonitorCommunicatio "bool";
BA_ "Bitfield" SG_ 421 cellboard6BmsMonitorCommunicatio "true";
BA_ "SystemSignalLongSymbol" SG_ 421 cellboard6BmsMonitorCommunicatio "cellboard6BmsMonitorCommunication";
BA_ "StandardName" SG_ 421 cellboard6Flash "Kraken_TsacCellboard6Error_flash_bool";
BA_ "SignalTypeName" SG_ 421 cellboard6Flash "bool";
BA_ "SignalType" SG_ 421 cellboard6Flash "bool";
BA_ "Bitfield" SG_ 421 cellboard6Flash "true";
BA_ "StandardName" SG_ 421 cellboard6CanCommunication "Kraken_TsacCellboard6Error_canCommunication_bool";
BA_ "SignalTypeName" SG_ 421 cellboard6CanCommunication "bool";
BA_ "SignalType" SG_ 421 cellboard6CanCommunication "bool";
BA_ "Bitfield" SG_ 421 cellboard6CanCommunication "true";
BA_ "StandardName" SG_ 421 cellboard6DischargeResistorOvert "Kraken_TsacCellboard6Error_dischargeResistorOvertemperature_bool";
BA_ "SignalTypeName" SG_ 421 cellboard6DischargeResistorOvert "bool";
BA_ "SignalType" SG_ 421 cellboard6DischargeResistorOvert "bool";
BA_ "Bitfield" SG_ 421 cellboard6DischargeResistorOvert "true";
BA_ "SystemSignalLongSymbol" SG_ 421 cellboard6DischargeResistorOvert "cellboard6DischargeResistorOvertemperature";
BA_ "StandardName" SG_ 421 cellboard6DischargeResistorUnder "Kraken_TsacCellboard6Error_dischargeResistorUndertemperature_bool";
BA_ "SignalTypeName" SG_ 421 cellboard6DischargeResistorUnder "bool";
BA_ "SignalType" SG_ 421 cellboard6DischargeResistorUnder "bool";
BA_ "Bitfield" SG_ 421 cellboard6DischargeResistorUnder "true";
BA_ "SystemSignalLongSymbol" SG_ 421 cellboard6DischargeResistorUnder "cellboard6DischargeResistorUndertemperature";
BA_ "StandardName" SG_ 421 cellboard6CellOvertemperature "Kraken_TsacCellboard6Error_cellOvertemperature_bool";
BA_ "SignalTypeName" SG_ 421 cellboard6CellOvertemperature "bool";
BA_ "SignalType" SG_ 421 cellboard6CellOvertemperature "bool";
BA_ "Bitfield" SG_ 421 cellboard6CellOvertemperature "true";
BA_ "StandardName" SG_ 421 cellboard6CellUndertemperature "Kraken_TsacCellboard6Error_cellUndertemperature_bool";
BA_ "SignalTypeName" SG_ 421 cellboard6CellUndertemperature "bool";
BA_ "SignalType" SG_ 421 cellboard6CellUndertemperature "bool";
BA_ "Bitfield" SG_ 421 cellboard6CellUndertemperature "true";
BA_ "StandardName" SG_ 421 cellboard6CellOvervoltage "Kraken_TsacCellboard6Error_cellOvervoltage_bool";
BA_ "SignalTypeName" SG_ 421 cellboard6CellOvervoltage "bool";
BA_ "SignalType" SG_ 421 cellboard6CellOvervoltage "bool";
BA_ "Bitfield" SG_ 421 cellboard6CellOvervoltage "true";
BA_ "StandardName" SG_ 421 cellboard6CellUndervoltage "Kraken_TsacCellboard6Error_cellUndervoltage_bool";
BA_ "SignalTypeName" SG_ 421 cellboard6CellUndervoltage "bool";
BA_ "SignalType" SG_ 421 cellboard6CellUndervoltage "bool";
BA_ "Bitfield" SG_ 421 cellboard6CellUndervoltage "true";
BA_ "StandardName" SG_ 421 cellboard6Post "Kraken_TsacCellboard6Error_post_bool";
BA_ "SignalTypeName" SG_ 421 cellboard6Post "bool";
BA_ "SignalType" SG_ 421 cellboard6Post "bool";
BA_ "Bitfield" SG_ 421 cellboard6Post "true";
BA_ "StandardName" SG_ 421 cellboard5OpenWire13 "Kraken_TsacCellboard5Error_openWire13_bool";
BA_ "SignalTypeName" SG_ 421 cellboard5OpenWire13 "bool";
BA_ "SignalType" SG_ 421 cellboard5OpenWire13 "bool";
BA_ "Bitfield" SG_ 421 cellboard5OpenWire13 "true";
BA_ "StandardName" SG_ 421 cellboard5OpenWire12 "Kraken_TsacCellboard5Error_openWire12_bool";
BA_ "SignalTypeName" SG_ 421 cellboard5OpenWire12 "bool";
BA_ "SignalType" SG_ 421 cellboard5OpenWire12 "bool";
BA_ "Bitfield" SG_ 421 cellboard5OpenWire12 "true";
BA_ "StandardName" SG_ 421 cellboard5OpenWire11 "Kraken_TsacCellboard5Error_openWire11_bool";
BA_ "SignalTypeName" SG_ 421 cellboard5OpenWire11 "bool";
BA_ "SignalType" SG_ 421 cellboard5OpenWire11 "bool";
BA_ "Bitfield" SG_ 421 cellboard5OpenWire11 "true";
BA_ "StandardName" SG_ 421 cellboard5OpenWire10 "Kraken_TsacCellboard5Error_openWire10_bool";
BA_ "SignalTypeName" SG_ 421 cellboard5OpenWire10 "bool";
BA_ "SignalType" SG_ 421 cellboard5OpenWire10 "bool";
BA_ "Bitfield" SG_ 421 cellboard5OpenWire10 "true";
BA_ "StandardName" SG_ 421 cellboard5OpenWire9 "Kraken_TsacCellboard5Error_openWire9_bool";
BA_ "SignalTypeName" SG_ 421 cellboard5OpenWire9 "bool";
BA_ "SignalType" SG_ 421 cellboard5OpenWire9 "bool";
BA_ "Bitfield" SG_ 421 cellboard5OpenWire9 "true";
BA_ "StandardName" SG_ 421 cellboard5OpenWire8 "Kraken_TsacCellboard5Error_openWire8_bool";
BA_ "SignalTypeName" SG_ 421 cellboard5OpenWire8 "bool";
BA_ "SignalType" SG_ 421 cellboard5OpenWire8 "bool";
BA_ "Bitfield" SG_ 421 cellboard5OpenWire8 "true";
BA_ "StandardName" SG_ 421 cellboard5OpenWire7 "Kraken_TsacCellboard5Error_openWire7_bool";
BA_ "SignalTypeName" SG_ 421 cellboard5OpenWire7 "bool";
BA_ "SignalType" SG_ 421 cellboard5OpenWire7 "bool";
BA_ "Bitfield" SG_ 421 cellboard5OpenWire7 "true";
BA_ "StandardName" SG_ 421 cellboard5OpenWire6 "Kraken_TsacCellboard5Error_openWire6_bool";
BA_ "SignalTypeName" SG_ 421 cellboard5OpenWire6 "bool";
BA_ "SignalType" SG_ 421 cellboard5OpenWire6 "bool";
BA_ "Bitfield" SG_ 421 cellboard5OpenWire6 "true";
BA_ "StandardName" SG_ 421 cellboard5OpenWire5 "Kraken_TsacCellboard5Error_openWire5_bool";
BA_ "SignalTypeName" SG_ 421 cellboard5OpenWire5 "bool";
BA_ "SignalType" SG_ 421 cellboard5OpenWire5 "bool";
BA_ "Bitfield" SG_ 421 cellboard5OpenWire5 "true";
BA_ "StandardName" SG_ 421 cellboard5OpenWire4 "Kraken_TsacCellboard5Error_openWire4_bool";
BA_ "SignalTypeName" SG_ 421 cellboard5OpenWire4 "bool";
BA_ "SignalType" SG_ 421 cellboard5OpenWire4 "bool";
BA_ "Bitfield" SG_ 421 cellboard5OpenWire4 "true";
BA_ "StandardName" SG_ 421 cellboard5OpenWire3 "Kraken_TsacCellboard5Error_openWire3_bool";
BA_ "SignalTypeName" SG_ 421 cellboard5OpenWire3 "bool";
BA_ "SignalType" SG_ 421 cellboard5OpenWire3 "bool";
BA_ "Bitfield" SG_ 421 cellboard5OpenWire3 "true";
BA_ "StandardName" SG_ 421 cellboard5OpenWire2 "Kraken_TsacCellboard5Error_openWire2_bool";
BA_ "SignalTypeName" SG_ 421 cellboard5OpenWire2 "bool";
BA_ "SignalType" SG_ 421 cellboard5OpenWire2 "bool";
BA_ "Bitfield" SG_ 421 cellboard5OpenWire2 "true";
BA_ "StandardName" SG_ 421 cellboard5OpenWire1 "Kraken_TsacCellboard5Error_openWire1_bool";
BA_ "SignalTypeName" SG_ 421 cellboard5OpenWire1 "bool";
BA_ "SignalType" SG_ 421 cellboard5OpenWire1 "bool";
BA_ "Bitfield" SG_ 421 cellboard5OpenWire1 "true";
BA_ "StandardName" SG_ 421 cellboard5BmsMonitorCommunicatio "Kraken_TsacCellboard5Error_bmsMonitorCommunication_bool";
BA_ "SignalTypeName" SG_ 421 cellboard5BmsMonitorCommunicatio "bool";
BA_ "SignalType" SG_ 421 cellboard5BmsMonitorCommunicatio "bool";
BA_ "Bitfield" SG_ 421 cellboard5BmsMonitorCommunicatio "true";
BA_ "SystemSignalLongSymbol" SG_ 421 cellboard5BmsMonitorCommunicatio "cellboard5BmsMonitorCommunication";
BA_ "StandardName" SG_ 421 cellboard5Flash "Kraken_TsacCellboard5Error_flash_bool";
BA_ "SignalTypeName" SG_ 421 cellboard5Flash "bool";
BA_ "SignalType" SG_ 421 cellboard5Flash "bool";
BA_ "Bitfield" SG_ 421 cellboard5Flash "true";
BA_ "StandardName" SG_ 421 cellboard5CanCommunication "Kraken_TsacCellboard5Error_canCommunication_bool";
BA_ "SignalTypeName" SG_ 421 cellboard5CanCommunication "bool";
BA_ "SignalType" SG_ 421 cellboard5CanCommunication "bool";
BA_ "Bitfield" SG_ 421 cellboard5CanCommunication "true";
BA_ "StandardName" SG_ 421 cellboard5DischargeResistorOvert "Kraken_TsacCellboard5Error_dischargeResistorOvertemperature_bool";
BA_ "SignalTypeName" SG_ 421 cellboard5DischargeResistorOvert "bool";
BA_ "SignalType" SG_ 421 cellboard5DischargeResistorOvert "bool";
BA_ "Bitfield" SG_ 421 cellboard5DischargeResistorOvert "true";
BA_ "SystemSignalLongSymbol" SG_ 421 cellboard5DischargeResistorOvert "cellboard5DischargeResistorOvertemperature";
BA_ "StandardName" SG_ 421 cellboard5DischargeResistorUnder "Kraken_TsacCellboard5Error_dischargeResistorUndertemperature_bool";
BA_ "SignalTypeName" SG_ 421 cellboard5DischargeResistorUnder "bool";
BA_ "SignalType" SG_ 421 cellboard5DischargeResistorUnder "bool";
BA_ "Bitfield" SG_ 421 cellboard5DischargeResistorUnder "true";
BA_ "SystemSignalLongSymbol" SG_ 421 cellboard5DischargeResistorUnder "cellboard5DischargeResistorUndertemperature";
BA_ "StandardName" SG_ 421 cellboard5CellOvertemperature "Kraken_TsacCellboard5Error_cellOvertemperature_bool";
BA_ "SignalTypeName" SG_ 421 cellboard5CellOvertemperature "bool";
BA_ "SignalType" SG_ 421 cellboard5CellOvertemperature "bool";
BA_ "Bitfield" SG_ 421 cellboard5CellOvertemperature "true";
BA_ "StandardName" SG_ 421 cellboard5CellUndertemperature "Kraken_TsacCellboard5Error_cellUndertemperature_bool";
BA_ "SignalTypeName" SG_ 421 cellboard5CellUndertemperature "bool";
BA_ "SignalType" SG_ 421 cellboard5CellUndertemperature "bool";
BA_ "Bitfield" SG_ 421 cellboard5CellUndertemperature "true";
BA_ "StandardName" SG_ 421 cellboard5CellOvervoltage "Kraken_TsacCellboard5Error_cellOvervoltage_bool";
BA_ "SignalTypeName" SG_ 421 cellboard5CellOvervoltage "bool";
BA_ "SignalType" SG_ 421 cellboard5CellOvervoltage "bool";
BA_ "Bitfield" SG_ 421 cellboard5CellOvervoltage "true";
BA_ "StandardName" SG_ 421 cellboard5CellUndervoltage "Kraken_TsacCellboard5Error_cellUndervoltage_bool";
BA_ "SignalTypeName" SG_ 421 cellboard5CellUndervoltage "bool";
BA_ "SignalType" SG_ 421 cellboard5CellUndervoltage "bool";
BA_ "Bitfield" SG_ 421 cellboard5CellUndervoltage "true";
BA_ "StandardName" SG_ 421 cellboard5Post "Kraken_TsacCellboard5Error_post_bool";
BA_ "SignalTypeName" SG_ 421 cellboard5Post "bool";
BA_ "SignalType" SG_ 421 cellboard5Post "bool";
BA_ "Bitfield" SG_ 421 cellboard5Post "true";
VAL_ 415 status 0 "SHORT_CIRCUIT" 1 "NORMAL" 2 "UNDERVOLTAGE" 3 "START_MEASURE" 4 "DEVICE_ERROR" 5 "EARTH_FAULT" 6 "INVALID" ;
VAL_ 416 imdStatus 0 "SHORT_CIRCUIT" 1 "NORMAL" 2 "UNDERVOLTAGE" 3 "START_MEASURE" 4 "DEVICE_ERROR" 5 "EARTH_FAULT" 6 "INVALID" ;

SIG_VALTYPE_ 1968 voltage : 1;
SIG_VALTYPE_ 1952 lockin_out : 1;
SIG_VALTYPE_ 1953 resistance : 1;
